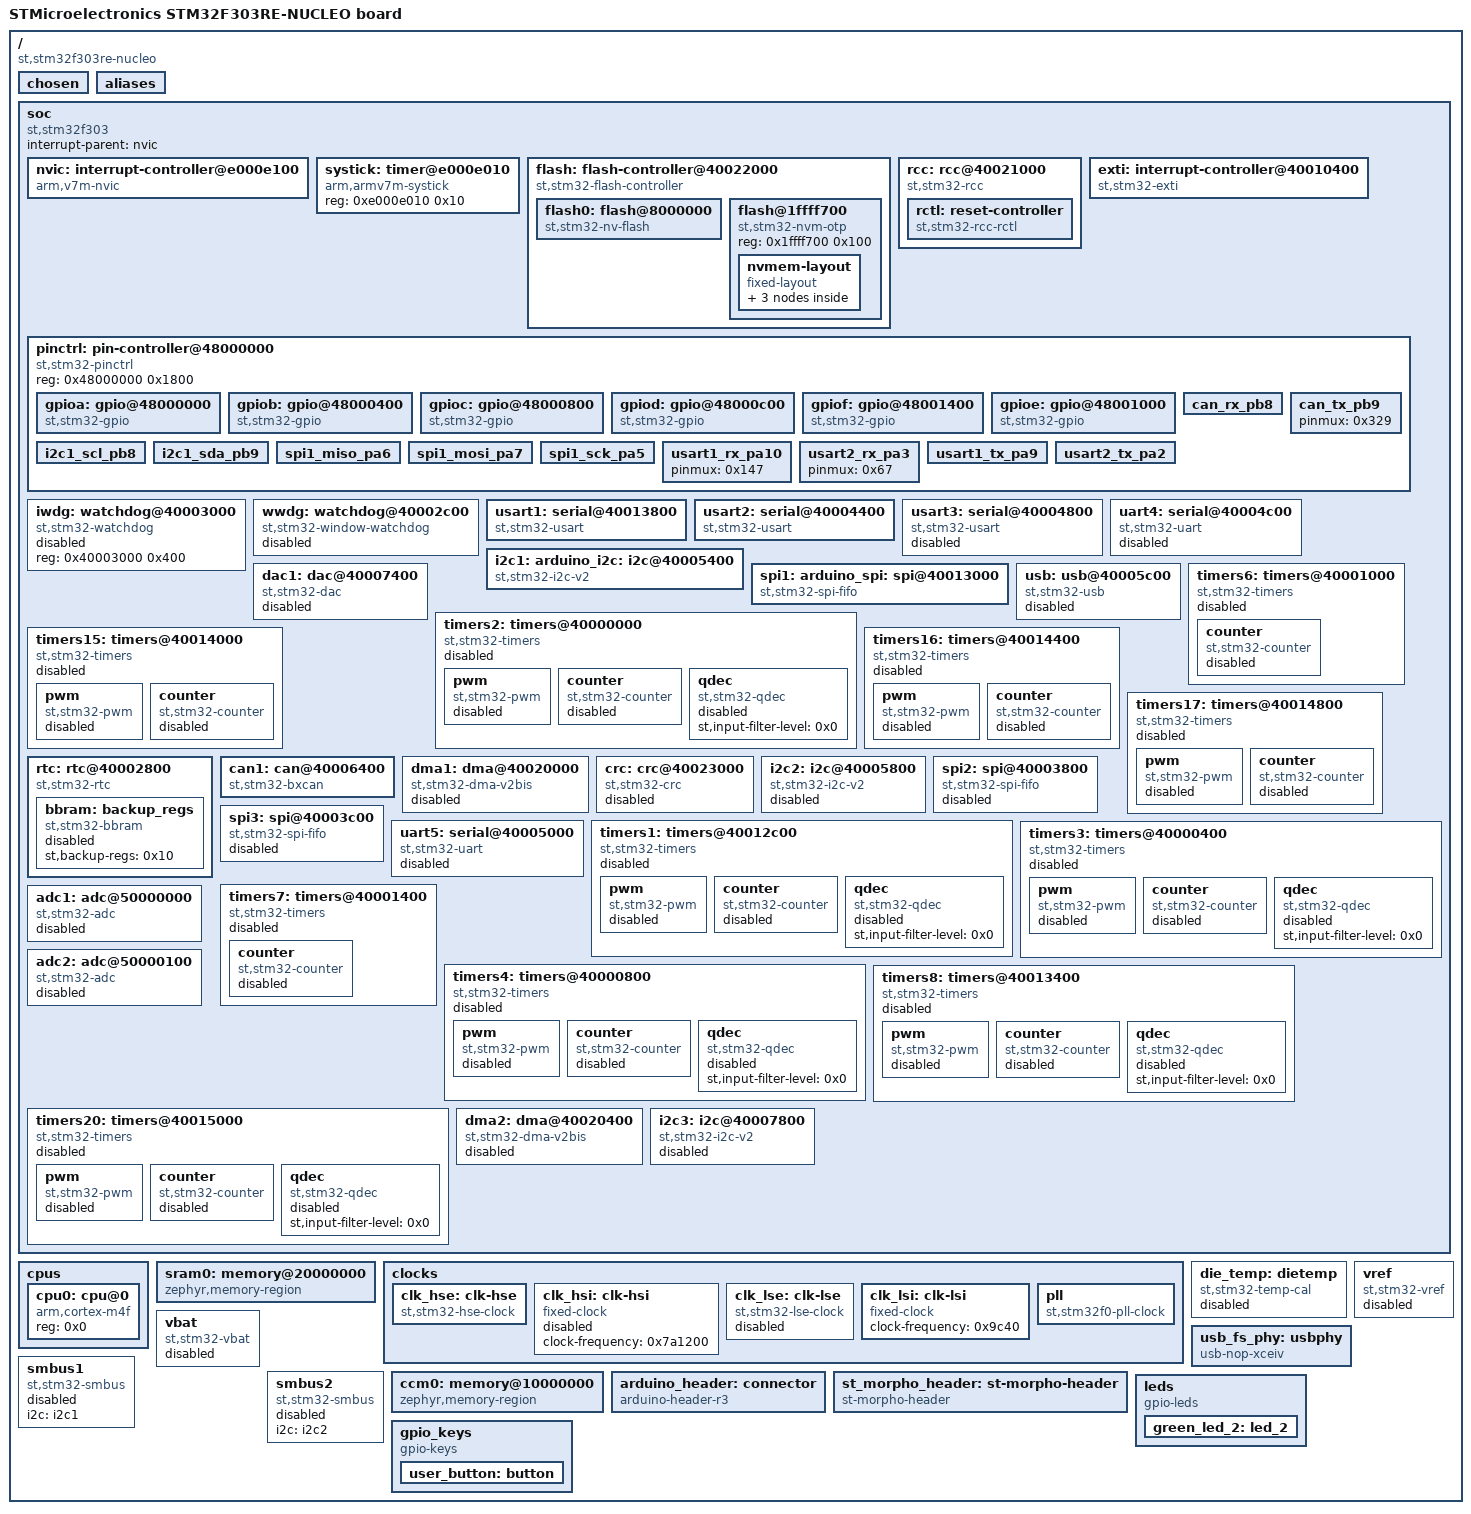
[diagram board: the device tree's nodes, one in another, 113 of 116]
/dts-v1/;

/* node '/' defined in zephyr/dts/common/skeleton.dtsi:9 */
/ {
	#address-cells = < 0x1 >;                              /* in zephyr/dts/common/skeleton.dtsi:10 */
	#size-cells = < 0x1 >;                                 /* in zephyr/dts/common/skeleton.dtsi:11 */
	model = "STMicroelectronics STM32F303RE-NUCLEO board"; /* in zephyr/boards/st/nucleo_f303re/nucleo_f303re.dts:15 */
	compatible = "st,stm32f303re-nucleo";                  /* in zephyr/boards/st/nucleo_f303re/nucleo_f303re.dts:16 */

	/* node '/chosen' defined in zephyr/dts/common/skeleton.dtsi:13 */
	chosen {
		zephyr,crc = &crc;                /* in zephyr/dts/arm/st/f3/stm32f3.dtsi:24 */
		zephyr,flash-controller = &flash; /* in zephyr/dts/arm/st/f3/stm32f3.dtsi:25 */
		zephyr,console = &usart2;         /* in zephyr/boards/st/nucleo_f303re/nucleo_f303re.dts:19 */
		zephyr,shell-uart = &usart2;      /* in zephyr/boards/st/nucleo_f303re/nucleo_f303re.dts:20 */
		zephyr,sram = &sram0;             /* in zephyr/boards/st/nucleo_f303re/nucleo_f303re.dts:21 */
		zephyr,flash = &flash0;           /* in zephyr/boards/st/nucleo_f303re/nucleo_f303re.dts:22 */
		zephyr,canbus = &can1;            /* in zephyr/boards/st/nucleo_f303re/nucleo_f303re.dts:23 */
	};

	/* node '/aliases' defined in zephyr/dts/common/skeleton.dtsi:15 */
	aliases {
		led0 = &green_led_2; /* in zephyr/boards/st/nucleo_f303re/nucleo_f303re.dts:46 */
		sw0 = &user_button;  /* in zephyr/boards/st/nucleo_f303re/nucleo_f303re.dts:47 */
	};

	/* node '/soc' defined in zephyr/dts/arm/armv7-m.dtsi:6 */
	soc {
		#address-cells = < 0x1 >;     /* in zephyr/dts/arm/armv7-m.dtsi:7 */
		#size-cells = < 0x1 >;        /* in zephyr/dts/arm/armv7-m.dtsi:8 */
		interrupt-parent = < &nvic >; /* in zephyr/dts/arm/armv7-m.dtsi:10 */
		ranges;                       /* in zephyr/dts/arm/armv7-m.dtsi:11 */
		compatible = "st,stm32f303",
		             "st,stm32f3",
		             "simple-bus";    /* in zephyr/dts/arm/st/f3/stm32f303.dtsi:12 */

		/* node '/soc/interrupt-controller@e000e100' defined in zephyr/dts/arm/armv7-m.dtsi:13 */
		nvic: interrupt-controller@e000e100 {
			#address-cells = < 0x1 >;            /* in zephyr/dts/arm/armv7-m.dtsi:14 */
			compatible = "arm,v7m-nvic";         /* in zephyr/dts/arm/armv7-m.dtsi:15 */
			reg = < 0xe000e100 0xc00 >;          /* in zephyr/dts/arm/armv7-m.dtsi:16 */
			interrupt-controller;                /* in zephyr/dts/arm/armv7-m.dtsi:17 */
			#interrupt-cells = < 0x2 >;          /* in zephyr/dts/arm/armv7-m.dtsi:18 */
			arm,num-irq-priority-bits = < 0x4 >; /* in zephyr/dts/arm/st/f3/stm32f3.dtsi:501 */
			phandle = < 0x1 >;                   /* in zephyr/dts/arm/armv7-m.dtsi:10 */
		};

		/* node '/soc/timer@e000e010' defined in zephyr/dts/arm/armv7-m.dtsi:21 */
		systick: timer@e000e010 {
			compatible = "arm,armv7m-systick"; /* in zephyr/dts/arm/armv7-m.dtsi:22 */
			reg = < 0xe000e010 0x10 >;         /* in zephyr/dts/arm/armv7-m.dtsi:23 */
		};

		/* node '/soc/flash-controller@40022000' defined in zephyr/dts/arm/st/f3/stm32f3.dtsi:81 */
		flash: flash-controller@40022000 {
			compatible = "st,stm32-flash-controller",
			             "st,stm32f1-flash-controller"; /* in zephyr/dts/arm/st/f3/stm32f3.dtsi:82 */
			reg = < 0x40022000 0x400 >;                 /* in zephyr/dts/arm/st/f3/stm32f3.dtsi:83 */
			interrupts = < 0x4 0x0 >;                   /* in zephyr/dts/arm/st/f3/stm32f3.dtsi:84 */
			clocks = < &rcc 0x14 0x10 >;                /* in zephyr/dts/arm/st/f3/stm32f3.dtsi:85 */
			#address-cells = < 0x1 >;                   /* in zephyr/dts/arm/st/f3/stm32f3.dtsi:87 */
			#size-cells = < 0x1 >;                      /* in zephyr/dts/arm/st/f3/stm32f3.dtsi:88 */
			ranges;                                     /* in zephyr/dts/arm/st/f3/stm32f3.dtsi:89 */

			/* node '/soc/flash-controller@40022000/flash@8000000' defined in zephyr/dts/arm/st/f3/stm32f3.dtsi:91 */
			flash0: flash@8000000 {
				compatible = "st,stm32-nv-flash",
				             "soc-nv-flash";        /* in zephyr/dts/arm/st/f3/stm32f3.dtsi:92 */
				#address-cells = < 0x1 >;           /* in zephyr/dts/arm/st/f3/stm32f3.dtsi:93 */
				#size-cells = < 0x1 >;              /* in zephyr/dts/arm/st/f3/stm32f3.dtsi:94 */
				write-block-size = < 0x2 >;         /* in zephyr/dts/arm/st/f3/stm32f3.dtsi:95 */
				erase-block-size = < 0x800 >;       /* in zephyr/dts/arm/st/f3/stm32f3.dtsi:96 */
				max-erase-time = < 0x28 >;          /* in zephyr/dts/arm/st/f3/stm32f3.dtsi:98 */
				reg = < 0x8000000 0x80000 >;        /* in zephyr/dts/arm/st/f3/stm32f303Xe.dtsi:23 */
				ranges = < 0x0 0x8000000 0x80000 >; /* in zephyr/dts/arm/st/f3/stm32f303Xe.dtsi:24 */
			};

			/* node '/soc/flash-controller@40022000/flash@1ffff700' defined in zephyr/dts/arm/st/f3/stm32f3.dtsi:105 */
			flash@1ffff700 {
				compatible = "st,stm32-nvm-otp"; /* in zephyr/dts/arm/st/f3/stm32f3.dtsi:106 */
				reg = < 0x1ffff700 0x100 >;      /* in zephyr/dts/arm/st/f3/stm32f3.dtsi:107 */

				/* node '/soc/flash-controller@40022000/flash@1ffff700/nvmem-layout' defined in zephyr/dts/arm/st/f3/stm32f3.dtsi:109 */
				nvmem-layout {
					compatible = "fixed-layout"; /* in zephyr/dts/arm/st/f3/stm32f3.dtsi:110 */
					#address-cells = < 0x1 >;    /* in zephyr/dts/arm/st/f3/stm32f3.dtsi:111 */
					#size-cells = < 0x1 >;       /* in zephyr/dts/arm/st/f3/stm32f3.dtsi:112 */

					/* node '/soc/flash-controller@40022000/flash@1ffff700/nvmem-layout/ts-cal1@b8' defined in zephyr/dts/arm/st/f3/stm32f3.dtsi:114 */
					ts_cal1_otp: ts-cal1@b8 {
						reg = < 0xb8 0x2 >;          /* in zephyr/dts/arm/st/f3/stm32f3.dtsi:115 */
						#nvmem-cell-cells = < 0x0 >; /* in zephyr/dts/arm/st/f3/stm32f3.dtsi:116 */
						read-only;                   /* in zephyr/dts/arm/st/f3/stm32f3.dtsi:117 */
						phandle = < 0x13 >;          /* in zephyr/dts/arm/st/f3/stm32f3.dtsi:462 */
					};

					/* node '/soc/flash-controller@40022000/flash@1ffff700/nvmem-layout/vrefint@ba' defined in zephyr/dts/arm/st/f3/stm32f3.dtsi:120 */
					vrefint_otp: vrefint@ba {
						reg = < 0xba 0x2 >;          /* in zephyr/dts/arm/st/f3/stm32f3.dtsi:121 */
						#nvmem-cell-cells = < 0x0 >; /* in zephyr/dts/arm/st/f3/stm32f3.dtsi:122 */
						read-only;                   /* in zephyr/dts/arm/st/f3/stm32f3.dtsi:123 */
						phandle = < 0x16 >;          /* in zephyr/dts/arm/st/f3/stm32f3.dtsi:473 */
					};

					/* node '/soc/flash-controller@40022000/flash@1ffff700/nvmem-layout/ts-cal2@c2' defined in zephyr/dts/arm/st/f3/stm32f3.dtsi:126 */
					ts_cal2_otp: ts-cal2@c2 {
						reg = < 0xc2 0x2 >;          /* in zephyr/dts/arm/st/f3/stm32f3.dtsi:127 */
						#nvmem-cell-cells = < 0x0 >; /* in zephyr/dts/arm/st/f3/stm32f3.dtsi:128 */
						read-only;                   /* in zephyr/dts/arm/st/f3/stm32f3.dtsi:129 */
						phandle = < 0x14 >;          /* in zephyr/dts/arm/st/f3/stm32f3.dtsi:462 */
					};
				};
			};
		};

		/* node '/soc/rcc@40021000' defined in zephyr/dts/arm/st/f3/stm32f3.dtsi:135 */
		rcc: rcc@40021000 {
			compatible = "st,stm32-rcc";     /* in zephyr/dts/arm/st/f3/stm32f3.dtsi:136 */
			#clock-cells = < 0x2 >;          /* in zephyr/dts/arm/st/f3/stm32f3.dtsi:137 */
			reg = < 0x40021000 0x400 >;      /* in zephyr/dts/arm/st/f3/stm32f3.dtsi:138 */
			clocks = < &pll >;               /* in zephyr/boards/st/nucleo_f303re/nucleo_f303re.dts:69 */
			clock-frequency = < 0x44aa200 >; /* in zephyr/boards/st/nucleo_f303re/nucleo_f303re.dts:70 */
			ahb-prescaler = < 0x1 >;         /* in zephyr/boards/st/nucleo_f303re/nucleo_f303re.dts:71 */
			apb1-prescaler = < 0x2 >;        /* in zephyr/boards/st/nucleo_f303re/nucleo_f303re.dts:72 */
			apb2-prescaler = < 0x1 >;        /* in zephyr/boards/st/nucleo_f303re/nucleo_f303re.dts:73 */
			phandle = < 0x2 >;               /* in zephyr/dts/arm/st/f3/stm32f3.dtsi:85 */

			/* node '/soc/rcc@40021000/reset-controller' defined in zephyr/dts/arm/st/f3/stm32f3.dtsi:140 */
			rctl: reset-controller {
				compatible = "st,stm32-rcc-rctl"; /* in zephyr/dts/arm/st/f3/stm32f3.dtsi:141 */
				#reset-cells = < 0x1 >;           /* in zephyr/dts/arm/st/f3/stm32f3.dtsi:142 */
				phandle = < 0x4 >;                /* in zephyr/dts/arm/st/f3/stm32f3.dtsi:227 */
			};
		};

		/* node '/soc/interrupt-controller@40010400' defined in zephyr/dts/arm/st/f3/stm32f3.dtsi:146 */
		exti: interrupt-controller@40010400 {
			compatible = "st,stm32-exti";  /* in zephyr/dts/arm/st/f3/stm32f3.dtsi:147 */
			interrupt-controller;          /* in zephyr/dts/arm/st/f3/stm32f3.dtsi:148 */
			#interrupt-cells = < 0x1 >;    /* in zephyr/dts/arm/st/f3/stm32f3.dtsi:149 */
			#address-cells = < 0x0 >;      /* in zephyr/dts/arm/st/f3/stm32f3.dtsi:150 */
			reg = < 0x40010400 0x400 >;    /* in zephyr/dts/arm/st/f3/stm32f3.dtsi:151 */
			clocks = < &rcc 0x18 0x1 >;    /* in zephyr/dts/arm/st/f3/stm32f3.dtsi:152 */
			num-lines = < 0x20 >;          /* in zephyr/dts/arm/st/f3/stm32f3.dtsi:153 */
			interrupts = < 0x6 0x0 >,
			             < 0x7 0x0 >,
			             < 0x8 0x0 >,
			             < 0x9 0x0 >,
			             < 0xa 0x0 >,
			             < 0x17 0x0 >,
			             < 0x28 0x0 >;     /* in zephyr/dts/arm/st/f3/stm32f3.dtsi:154 */
			interrupt-names = "line0",
			                  "line1",
			                  "line2",
			                  "line3",
			                  "line4",
			                  "line5-9",
			                  "line10-15"; /* in zephyr/dts/arm/st/f3/stm32f3.dtsi:156 */
			line-ranges = < 0x0 0x1 >,
			              < 0x1 0x1 >,
			              < 0x2 0x1 >,
			              < 0x3 0x1 >,
			              < 0x4 0x1 >,
			              < 0x5 0x5 >,
			              < 0xa 0x6 >;     /* in zephyr/dts/arm/st/f3/stm32f3.dtsi:158 */
		};

		/* node '/soc/pin-controller@48000000' defined in zephyr/dts/arm/st/f3/stm32f3.dtsi:162 */
		pinctrl: pin-controller@48000000 {
			compatible = "st,stm32-pinctrl"; /* in zephyr/dts/arm/st/f3/stm32f3.dtsi:163 */
			#address-cells = < 0x1 >;        /* in zephyr/dts/arm/st/f3/stm32f3.dtsi:164 */
			#size-cells = < 0x1 >;           /* in zephyr/dts/arm/st/f3/stm32f3.dtsi:165 */
			reg = < 0x48000000 0x1800 >;     /* in zephyr/dts/arm/st/f3/stm32f3.dtsi:166 */

			/* node '/soc/pin-controller@48000000/gpio@48000000' defined in zephyr/dts/arm/st/f3/stm32f3.dtsi:168 */
			gpioa: gpio@48000000 {
				compatible = "st,stm32-gpio";   /* in zephyr/dts/arm/st/f3/stm32f3.dtsi:169 */
				gpio-controller;                /* in zephyr/dts/arm/st/f3/stm32f3.dtsi:170 */
				#gpio-cells = < 0x2 >;          /* in zephyr/dts/arm/st/f3/stm32f3.dtsi:171 */
				reg = < 0x48000000 0x400 >;     /* in zephyr/dts/arm/st/f3/stm32f3.dtsi:172 */
				clocks = < &rcc 0x14 0x20000 >; /* in zephyr/dts/arm/st/f3/stm32f3.dtsi:173 */
				phandle = < 0x19 >;             /* in zephyr/boards/st/nucleo_f303re/arduino_r3_connector.dtsi:15 */
			};

			/* node '/soc/pin-controller@48000000/gpio@48000400' defined in zephyr/dts/arm/st/f3/stm32f3.dtsi:176 */
			gpiob: gpio@48000400 {
				compatible = "st,stm32-gpio";   /* in zephyr/dts/arm/st/f3/stm32f3.dtsi:177 */
				gpio-controller;                /* in zephyr/dts/arm/st/f3/stm32f3.dtsi:178 */
				#gpio-cells = < 0x2 >;          /* in zephyr/dts/arm/st/f3/stm32f3.dtsi:179 */
				reg = < 0x48000400 0x400 >;     /* in zephyr/dts/arm/st/f3/stm32f3.dtsi:180 */
				clocks = < &rcc 0x14 0x40000 >; /* in zephyr/dts/arm/st/f3/stm32f3.dtsi:181 */
				phandle = < 0xb >;              /* in zephyr/boards/st/nucleo_f303re/nucleo_f303re.dts:107 */
			};

			/* node '/soc/pin-controller@48000000/gpio@48000800' defined in zephyr/dts/arm/st/f3/stm32f3.dtsi:184 */
			gpioc: gpio@48000800 {
				compatible = "st,stm32-gpio";   /* in zephyr/dts/arm/st/f3/stm32f3.dtsi:185 */
				gpio-controller;                /* in zephyr/dts/arm/st/f3/stm32f3.dtsi:186 */
				#gpio-cells = < 0x2 >;          /* in zephyr/dts/arm/st/f3/stm32f3.dtsi:187 */
				reg = < 0x48000800 0x400 >;     /* in zephyr/dts/arm/st/f3/stm32f3.dtsi:188 */
				clocks = < &rcc 0x14 0x80000 >; /* in zephyr/dts/arm/st/f3/stm32f3.dtsi:189 */
				phandle = < 0x1a >;             /* in zephyr/boards/st/nucleo_f303re/arduino_r3_connector.dtsi:15 */
			};

			/* node '/soc/pin-controller@48000000/gpio@48000c00' defined in zephyr/dts/arm/st/f3/stm32f3.dtsi:192 */
			gpiod: gpio@48000c00 {
				compatible = "st,stm32-gpio";    /* in zephyr/dts/arm/st/f3/stm32f3.dtsi:193 */
				gpio-controller;                 /* in zephyr/dts/arm/st/f3/stm32f3.dtsi:194 */
				#gpio-cells = < 0x2 >;           /* in zephyr/dts/arm/st/f3/stm32f3.dtsi:195 */
				reg = < 0x48000c00 0x400 >;      /* in zephyr/dts/arm/st/f3/stm32f3.dtsi:196 */
				clocks = < &rcc 0x14 0x100000 >; /* in zephyr/dts/arm/st/f3/stm32f3.dtsi:197 */
				phandle = < 0x1b >;              /* in zephyr/boards/st/nucleo_f303re/st_morpho_connector.dtsi:15 */
			};

			/* node '/soc/pin-controller@48000000/gpio@48001400' defined in zephyr/dts/arm/st/f3/stm32f3.dtsi:200 */
			gpiof: gpio@48001400 {
				compatible = "st,stm32-gpio";    /* in zephyr/dts/arm/st/f3/stm32f3.dtsi:201 */
				gpio-controller;                 /* in zephyr/dts/arm/st/f3/stm32f3.dtsi:202 */
				#gpio-cells = < 0x2 >;           /* in zephyr/dts/arm/st/f3/stm32f3.dtsi:203 */
				reg = < 0x48001400 0x400 >;      /* in zephyr/dts/arm/st/f3/stm32f3.dtsi:204 */
				clocks = < &rcc 0x14 0x400000 >; /* in zephyr/dts/arm/st/f3/stm32f3.dtsi:205 */
				phandle = < 0x1c >;              /* in zephyr/boards/st/nucleo_f303re/st_morpho_connector.dtsi:15 */
			};

			/* node '/soc/pin-controller@48000000/gpio@48001000' defined in zephyr/dts/arm/st/f3/stm32f303.dtsi:67 */
			gpioe: gpio@48001000 {
				compatible = "st,stm32-gpio";    /* in zephyr/dts/arm/st/f3/stm32f303.dtsi:68 */
				gpio-controller;                 /* in zephyr/dts/arm/st/f3/stm32f303.dtsi:69 */
				#gpio-cells = < 0x2 >;           /* in zephyr/dts/arm/st/f3/stm32f303.dtsi:70 */
				reg = < 0x48001000 0x400 >;      /* in zephyr/dts/arm/st/f3/stm32f303.dtsi:71 */
				clocks = < &rcc 0x14 0x200000 >; /* in zephyr/dts/arm/st/f3/stm32f303.dtsi:72 */
			};

			/* node '/soc/pin-controller@48000000/can_rx_pb8' defined in modules/hal/stm32/dts/st/f3/stm32f303r(d-e)tx-pinctrl.dtsi:334 */
			can_rx_pb8: can_rx_pb8 {
				pinmux = < 0x309 >; /* in modules/hal/stm32/dts/st/f3/stm32f303r(d-e)tx-pinctrl.dtsi:335 */
				bias-pull-up;       /* in modules/hal/stm32/dts/st/f3/stm32f303r(d-e)tx-pinctrl.dtsi:336 */
				phandle = < 0x10 >; /* in zephyr/boards/st/nucleo_f303re/nucleo_f303re.dts:97 */
			};

			/* node '/soc/pin-controller@48000000/can_tx_pb9' defined in modules/hal/stm32/dts/st/f3/stm32f303r(d-e)tx-pinctrl.dtsi:345 */
			can_tx_pb9: can_tx_pb9 {
				pinmux = < 0x329 >; /* in modules/hal/stm32/dts/st/f3/stm32f303r(d-e)tx-pinctrl.dtsi:346 */
				phandle = < 0x11 >; /* in zephyr/boards/st/nucleo_f303re/nucleo_f303re.dts:97 */
			};

			/* node '/soc/pin-controller@48000000/i2c1_scl_pb8' defined in modules/hal/stm32/dts/st/f3/stm32f303r(d-e)tx-pinctrl.dtsi:549 */
			i2c1_scl_pb8: i2c1_scl_pb8 {
				pinmux = < 0x304 >; /* in modules/hal/stm32/dts/st/f3/stm32f303r(d-e)tx-pinctrl.dtsi:550 */
				bias-pull-up;       /* in modules/hal/stm32/dts/st/f3/stm32f303r(d-e)tx-pinctrl.dtsi:551 */
				drive-open-drain;   /* in modules/hal/stm32/dts/st/f3/stm32f303r(d-e)tx-pinctrl.dtsi:552 */
				phandle = < 0x9 >;  /* in zephyr/boards/st/nucleo_f303re/nucleo_f303re.dts:103 */
			};

			/* node '/soc/pin-controller@48000000/i2c1_sda_pb9' defined in modules/hal/stm32/dts/st/f3/stm32f303r(d-e)tx-pinctrl.dtsi:587 */
			i2c1_sda_pb9: i2c1_sda_pb9 {
				pinmux = < 0x324 >; /* in modules/hal/stm32/dts/st/f3/stm32f303r(d-e)tx-pinctrl.dtsi:588 */
				bias-pull-up;       /* in modules/hal/stm32/dts/st/f3/stm32f303r(d-e)tx-pinctrl.dtsi:589 */
				drive-open-drain;   /* in modules/hal/stm32/dts/st/f3/stm32f303r(d-e)tx-pinctrl.dtsi:590 */
				phandle = < 0xa >;  /* in zephyr/boards/st/nucleo_f303re/nucleo_f303re.dts:103 */
			};

			/* node '/soc/pin-controller@48000000/spi1_miso_pa6' defined in modules/hal/stm32/dts/st/f3/stm32f303r(d-e)tx-pinctrl.dtsi:852 */
			spi1_miso_pa6: spi1_miso_pa6 {
				pinmux = < 0xc5 >;             /* in modules/hal/stm32/dts/st/f3/stm32f303r(d-e)tx-pinctrl.dtsi:853 */
				bias-pull-down;                /* in modules/hal/stm32/dts/st/f3/stm32f303r(d-e)tx-pinctrl.dtsi:854 */
				slew-rate = "very-high-speed"; /* in modules/hal/stm32/dts/st/f3/stm32f303r(d-e)tx-pinctrl.dtsi:855 */
				phandle = < 0xd >;             /* in nucleo_f303re.overlay:2 */
			};

			/* node '/soc/pin-controller@48000000/spi1_mosi_pa7' defined in modules/hal/stm32/dts/st/f3/stm32f303r(d-e)tx-pinctrl.dtsi:890 */
			spi1_mosi_pa7: spi1_mosi_pa7 {
				pinmux = < 0xe5 >;             /* in modules/hal/stm32/dts/st/f3/stm32f303r(d-e)tx-pinctrl.dtsi:891 */
				bias-pull-down;                /* in modules/hal/stm32/dts/st/f3/stm32f303r(d-e)tx-pinctrl.dtsi:892 */
				slew-rate = "very-high-speed"; /* in modules/hal/stm32/dts/st/f3/stm32f303r(d-e)tx-pinctrl.dtsi:893 */
				phandle = < 0xc >;             /* in nucleo_f303re.overlay:2 */
			};

			/* node '/soc/pin-controller@48000000/spi1_sck_pa5' defined in modules/hal/stm32/dts/st/f3/stm32f303r(d-e)tx-pinctrl.dtsi:966 */
			spi1_sck_pa5: spi1_sck_pa5 {
				pinmux = < 0xa5 >;             /* in modules/hal/stm32/dts/st/f3/stm32f303r(d-e)tx-pinctrl.dtsi:967 */
				bias-pull-down;                /* in modules/hal/stm32/dts/st/f3/stm32f303r(d-e)tx-pinctrl.dtsi:968 */
				slew-rate = "very-high-speed"; /* in modules/hal/stm32/dts/st/f3/stm32f303r(d-e)tx-pinctrl.dtsi:969 */
				phandle = < 0xe >;             /* in nucleo_f303re.overlay:2 */
			};

			/* node '/soc/pin-controller@48000000/usart1_rx_pa10' defined in modules/hal/stm32/dts/st/f3/stm32f303r(d-e)tx-pinctrl.dtsi:1578 */
			usart1_rx_pa10: usart1_rx_pa10 {
				pinmux = < 0x147 >; /* in modules/hal/stm32/dts/st/f3/stm32f303r(d-e)tx-pinctrl.dtsi:1579 */
				phandle = < 0x6 >;  /* in zephyr/boards/st/nucleo_f303re/nucleo_f303re.dts:84 */
			};

			/* node '/soc/pin-controller@48000000/usart2_rx_pa3' defined in modules/hal/stm32/dts/st/f3/stm32f303r(d-e)tx-pinctrl.dtsi:1590 */
			usart2_rx_pa3: usart2_rx_pa3 {
				pinmux = < 0x67 >; /* in modules/hal/stm32/dts/st/f3/stm32f303r(d-e)tx-pinctrl.dtsi:1591 */
				phandle = < 0x8 >; /* in zephyr/boards/st/nucleo_f303re/nucleo_f303re.dts:77 */
			};

			/* node '/soc/pin-controller@48000000/usart1_tx_pa9' defined in modules/hal/stm32/dts/st/f3/stm32f303r(d-e)tx-pinctrl.dtsi:1624 */
			usart1_tx_pa9: usart1_tx_pa9 {
				pinmux = < 0x127 >; /* in modules/hal/stm32/dts/st/f3/stm32f303r(d-e)tx-pinctrl.dtsi:1625 */
				bias-pull-up;       /* in modules/hal/stm32/dts/st/f3/stm32f303r(d-e)tx-pinctrl.dtsi:1626 */
				phandle = < 0x5 >;  /* in zephyr/boards/st/nucleo_f303re/nucleo_f303re.dts:84 */
			};

			/* node '/soc/pin-controller@48000000/usart2_tx_pa2' defined in modules/hal/stm32/dts/st/f3/stm32f303r(d-e)tx-pinctrl.dtsi:1639 */
			usart2_tx_pa2: usart2_tx_pa2 {
				pinmux = < 0x47 >; /* in modules/hal/stm32/dts/st/f3/stm32f303r(d-e)tx-pinctrl.dtsi:1640 */
				bias-pull-up;      /* in modules/hal/stm32/dts/st/f3/stm32f303r(d-e)tx-pinctrl.dtsi:1641 */
				phandle = < 0x7 >; /* in zephyr/boards/st/nucleo_f303re/nucleo_f303re.dts:77 */
			};
		};

		/* node '/soc/watchdog@40003000' defined in zephyr/dts/arm/st/f3/stm32f3.dtsi:209 */
		iwdg: watchdog@40003000 {
			compatible = "st,stm32-watchdog"; /* in zephyr/dts/arm/st/f3/stm32f3.dtsi:210 */
			reg = < 0x40003000 0x400 >;       /* in zephyr/dts/arm/st/f3/stm32f3.dtsi:211 */
			status = "disabled";              /* in zephyr/dts/arm/st/f3/stm32f3.dtsi:212 */
		};

		/* node '/soc/watchdog@40002c00' defined in zephyr/dts/arm/st/f3/stm32f3.dtsi:215 */
		wwdg: watchdog@40002c00 {
			compatible = "st,stm32-window-watchdog"; /* in zephyr/dts/arm/st/f3/stm32f3.dtsi:216 */
			reg = < 0x40002c00 0x400 >;              /* in zephyr/dts/arm/st/f3/stm32f3.dtsi:217 */
			clocks = < &rcc 0x1c 0x800 >;            /* in zephyr/dts/arm/st/f3/stm32f3.dtsi:218 */
			interrupts = < 0x0 0x0 >;                /* in zephyr/dts/arm/st/f3/stm32f3.dtsi:219 */
			status = "disabled";                     /* in zephyr/dts/arm/st/f3/stm32f3.dtsi:220 */
		};

		/* node '/soc/serial@40013800' defined in zephyr/dts/arm/st/f3/stm32f3.dtsi:223 */
		usart1: serial@40013800 {
			compatible = "st,stm32-usart",
			             "st,stm32-uart";                   /* in zephyr/dts/arm/st/f3/stm32f3.dtsi:224 */
			reg = < 0x40013800 0x400 >;                     /* in zephyr/dts/arm/st/f3/stm32f3.dtsi:225 */
			clocks = < &rcc 0x18 0x4000 >;                  /* in zephyr/dts/arm/st/f3/stm32f3.dtsi:226 */
			resets = < &rctl 0x18e >;                       /* in zephyr/dts/arm/st/f3/stm32f3.dtsi:227 */
			interrupts = < 0x25 0x0 >;                      /* in zephyr/dts/arm/st/f3/stm32f3.dtsi:228 */
			pinctrl-0 = < &usart1_tx_pa9 &usart1_rx_pa10 >; /* in zephyr/boards/st/nucleo_f303re/nucleo_f303re.dts:84 */
			pinctrl-names = "default";                      /* in zephyr/boards/st/nucleo_f303re/nucleo_f303re.dts:85 */
			current-speed = < 0x1c200 >;                    /* in zephyr/boards/st/nucleo_f303re/nucleo_f303re.dts:86 */
			status = "okay";                                /* in zephyr/boards/st/nucleo_f303re/nucleo_f303re.dts:87 */
		};

		/* node '/soc/serial@40004400' defined in zephyr/dts/arm/st/f3/stm32f3.dtsi:232 */
		usart2: serial@40004400 {
			compatible = "st,stm32-usart",
			             "st,stm32-uart";                  /* in zephyr/dts/arm/st/f3/stm32f3.dtsi:233 */
			reg = < 0x40004400 0x400 >;                    /* in zephyr/dts/arm/st/f3/stm32f3.dtsi:234 */
			clocks = < &rcc 0x1c 0x20000 >;                /* in zephyr/dts/arm/st/f3/stm32f3.dtsi:235 */
			resets = < &rctl 0x211 >;                      /* in zephyr/dts/arm/st/f3/stm32f3.dtsi:236 */
			interrupts = < 0x26 0x0 >;                     /* in zephyr/dts/arm/st/f3/stm32f3.dtsi:237 */
			pinctrl-0 = < &usart2_tx_pa2 &usart2_rx_pa3 >; /* in zephyr/boards/st/nucleo_f303re/nucleo_f303re.dts:77 */
			pinctrl-names = "default";                     /* in zephyr/boards/st/nucleo_f303re/nucleo_f303re.dts:78 */
			current-speed = < 0x1c200 >;                   /* in zephyr/boards/st/nucleo_f303re/nucleo_f303re.dts:79 */
			status = "okay";                               /* in zephyr/boards/st/nucleo_f303re/nucleo_f303re.dts:80 */
		};

		/* node '/soc/serial@40004800' defined in zephyr/dts/arm/st/f3/stm32f3.dtsi:241 */
		usart3: serial@40004800 {
			compatible = "st,stm32-usart",
			             "st,stm32-uart";   /* in zephyr/dts/arm/st/f3/stm32f3.dtsi:242 */
			reg = < 0x40004800 0x400 >;     /* in zephyr/dts/arm/st/f3/stm32f3.dtsi:243 */
			clocks = < &rcc 0x1c 0x40000 >; /* in zephyr/dts/arm/st/f3/stm32f3.dtsi:244 */
			resets = < &rctl 0x212 >;       /* in zephyr/dts/arm/st/f3/stm32f3.dtsi:245 */
			interrupts = < 0x27 0x0 >;      /* in zephyr/dts/arm/st/f3/stm32f3.dtsi:246 */
			status = "disabled";            /* in zephyr/dts/arm/st/f3/stm32f3.dtsi:247 */
		};

		/* node '/soc/serial@40004c00' defined in zephyr/dts/arm/st/f3/stm32f3.dtsi:250 */
		uart4: serial@40004c00 {
			compatible = "st,stm32-uart";   /* in zephyr/dts/arm/st/f3/stm32f3.dtsi:251 */
			reg = < 0x40004c00 0x400 >;     /* in zephyr/dts/arm/st/f3/stm32f3.dtsi:252 */
			clocks = < &rcc 0x1c 0x80000 >; /* in zephyr/dts/arm/st/f3/stm32f3.dtsi:253 */
			resets = < &rctl 0x213 >;       /* in zephyr/dts/arm/st/f3/stm32f3.dtsi:254 */
			interrupts = < 0x34 0x0 >;      /* in zephyr/dts/arm/st/f3/stm32f3.dtsi:255 */
			status = "disabled";            /* in zephyr/dts/arm/st/f3/stm32f3.dtsi:256 */
		};

		/* node '/soc/i2c@40005400' defined in zephyr/dts/arm/st/f3/stm32f3.dtsi:259 */
		i2c1: arduino_i2c: i2c@40005400 {
			compatible = "st,stm32-i2c-v2";              /* in zephyr/dts/arm/st/f3/stm32f3.dtsi:260 */
			#address-cells = < 0x1 >;                    /* in zephyr/dts/arm/st/f3/stm32f3.dtsi:262 */
			#size-cells = < 0x0 >;                       /* in zephyr/dts/arm/st/f3/stm32f3.dtsi:263 */
			reg = < 0x40005400 0x400 >;                  /* in zephyr/dts/arm/st/f3/stm32f3.dtsi:264 */
			clocks = < &rcc 0x1c 0x200000 >,
			         < &rcc 0x1 0x1040030 >;             /* in zephyr/dts/arm/st/f3/stm32f3.dtsi:265 */
			interrupts = < 0x1f 0x0 >,
			             < 0x20 0x0 >;                   /* in zephyr/dts/arm/st/f3/stm32f3.dtsi:270 */
			interrupt-names = "event",
			                  "error";                   /* in zephyr/dts/arm/st/f3/stm32f3.dtsi:271 */
			pinctrl-0 = < &i2c1_scl_pb8 &i2c1_sda_pb9 >; /* in zephyr/boards/st/nucleo_f303re/nucleo_f303re.dts:103 */
			status = "okay";                             /* in zephyr/boards/st/nucleo_f303re/nucleo_f303re.dts:104 */
			pinctrl-names = "default";                   /* in zephyr/boards/st/nucleo_f303re/nucleo_f303re.dts:105 */
			clock-frequency = < 0x186a0 >;               /* in zephyr/boards/st/nucleo_f303re/nucleo_f303re.dts:106 */
			scl-gpios = < &gpiob 0x8 0x0 >;              /* in zephyr/boards/st/nucleo_f303re/nucleo_f303re.dts:107 */
			sda-gpios = < &gpiob 0x9 0x0 >;              /* in zephyr/boards/st/nucleo_f303re/nucleo_f303re.dts:108 */
			phandle = < 0x17 >;                          /* in zephyr/dts/arm/st/f3/stm32f3.dtsi:495 */
		};

		/* node '/soc/spi@40013000' defined in zephyr/dts/arm/st/f3/stm32f3.dtsi:275 */
		spi1: arduino_spi: spi@40013000 {
			compatible = "st,stm32-spi-fifo",
			             "st,stm32-spi";                                 /* in zephyr/dts/arm/st/f3/stm32f3.dtsi:276 */
			#address-cells = < 0x1 >;                                    /* in zephyr/dts/arm/st/f3/stm32f3.dtsi:277 */
			#size-cells = < 0x0 >;                                       /* in zephyr/dts/arm/st/f3/stm32f3.dtsi:278 */
			reg = < 0x40013000 0x400 >;                                  /* in zephyr/dts/arm/st/f3/stm32f3.dtsi:279 */
			clocks = < &rcc 0x18 0x1000 >;                               /* in zephyr/dts/arm/st/f3/stm32f3.dtsi:280 */
			interrupts = < 0x23 0x0 >;                                   /* in zephyr/dts/arm/st/f3/stm32f3.dtsi:281 */
			st,spi-data-width = "full-4-to-16-bit";                      /* in zephyr/dts/arm/st/f3/stm32f3.dtsi:282 */
			pinctrl-0 = < &spi1_mosi_pa7 &spi1_miso_pa6 &spi1_sck_pa5 >; /* in nucleo_f303re.overlay:2 */
			pinctrl-names = "default";                                   /* in nucleo_f303re.overlay:3 */
			cs-gpios = < &gpiob 0x6 0x0 >;                               /* in nucleo_f303re.overlay:4 */
			status = "okay";                                             /* in nucleo_f303re.overlay:5 */
		};

		/* node '/soc/dac@40007400' defined in zephyr/dts/arm/st/f3/stm32f3.dtsi:286 */
		dac1: dac@40007400 {
			compatible = "st,stm32-dac";       /* in zephyr/dts/arm/st/f3/stm32f3.dtsi:287 */
			reg = < 0x40007400 0x400 >;        /* in zephyr/dts/arm/st/f3/stm32f3.dtsi:288 */
			clocks = < &rcc 0x1c 0x20000000 >; /* in zephyr/dts/arm/st/f3/stm32f3.dtsi:289 */
			status = "disabled";               /* in zephyr/dts/arm/st/f3/stm32f3.dtsi:290 */
			#io-channel-cells = < 0x1 >;       /* in zephyr/dts/arm/st/f3/stm32f3.dtsi:291 */
		};

		/* node '/soc/usb@40005c00' defined in zephyr/dts/arm/st/f3/stm32f3.dtsi:294 */
		usb: usb@40005c00 {
			compatible = "st,stm32-usb";     /* in zephyr/dts/arm/st/f3/stm32f3.dtsi:295 */
			reg = < 0x40005c00 0x400 >;      /* in zephyr/dts/arm/st/f3/stm32f3.dtsi:296 */
			interrupt-names = "usb";         /* in zephyr/dts/arm/st/f3/stm32f3.dtsi:298 */
			num-bidir-endpoints = < 0x8 >;   /* in zephyr/dts/arm/st/f3/stm32f3.dtsi:299 */
			ram-size = < 0x200 >;            /* in zephyr/dts/arm/st/f3/stm32f3.dtsi:300 */
			maximum-speed = "full-speed";    /* in zephyr/dts/arm/st/f3/stm32f3.dtsi:301 */
			phys = < &usb_fs_phy >;          /* in zephyr/dts/arm/st/f3/stm32f3.dtsi:302 */
			clocks = < &rcc 0x1c 0x800000 >; /* in zephyr/dts/arm/st/f3/stm32f3.dtsi:303 */
			status = "disabled";             /* in zephyr/dts/arm/st/f3/stm32f3.dtsi:304 */
			interrupts = < 0x4b 0x0 >;       /* in zephyr/dts/arm/st/f3/stm32f303.dtsi:16 */
		};

		/* node '/soc/timers@40000000' defined in zephyr/dts/arm/st/f3/stm32f3.dtsi:307 */
		timers2: timers@40000000 {
			compatible = "st,stm32-timers"; /* in zephyr/dts/arm/st/f3/stm32f3.dtsi:308 */
			reg = < 0x40000000 0x400 >;     /* in zephyr/dts/arm/st/f3/stm32f3.dtsi:309 */
			resets = < &rctl 0x200 >;       /* in zephyr/dts/arm/st/f3/stm32f3.dtsi:312 */
			interrupts = < 0x1c 0x0 >;      /* in zephyr/dts/arm/st/f3/stm32f3.dtsi:313 */
			interrupt-names = "global";     /* in zephyr/dts/arm/st/f3/stm32f3.dtsi:314 */
			st,prescaler = < 0x0 >;         /* in zephyr/dts/arm/st/f3/stm32f3.dtsi:315 */
			status = "disabled";            /* in zephyr/dts/arm/st/f3/stm32f3.dtsi:316 */
			clocks = < &rcc 0x1c 0x1 >,
			         < &rcc 0x6 0x180030 >; /* in zephyr/dts/arm/st/f3/stm32f303Xe.dtsi:29 */

			/* node '/soc/timers@40000000/pwm' defined in zephyr/dts/arm/st/f3/stm32f3.dtsi:318 */
			pwm {
				compatible = "st,stm32-pwm"; /* in zephyr/dts/arm/st/f3/stm32f3.dtsi:319 */
				status = "disabled";         /* in zephyr/dts/arm/st/f3/stm32f3.dtsi:320 */
				#pwm-cells = < 0x3 >;        /* in zephyr/dts/arm/st/f3/stm32f3.dtsi:321 */
			};

			/* node '/soc/timers@40000000/counter' defined in zephyr/dts/arm/st/f3/stm32f3.dtsi:324 */
			counter {
				compatible = "st,stm32-counter"; /* in zephyr/dts/arm/st/f3/stm32f3.dtsi:325 */
				status = "disabled";             /* in zephyr/dts/arm/st/f3/stm32f3.dtsi:326 */
			};

			/* node '/soc/timers@40000000/qdec' defined in zephyr/dts/arm/st/f3/stm32f3.dtsi:329 */
			qdec {
				compatible = "st,stm32-qdec";    /* in zephyr/dts/arm/st/f3/stm32f3.dtsi:330 */
				st,input-filter-level = < 0x0 >; /* in zephyr/dts/arm/st/f3/stm32f3.dtsi:331 */
				status = "disabled";             /* in zephyr/dts/arm/st/f3/stm32f3.dtsi:332 */
			};
		};

		/* node '/soc/timers@40001000' defined in zephyr/dts/arm/st/f3/stm32f3.dtsi:336 */
		timers6: timers@40001000 {
			compatible = "st,stm32-timers"; /* in zephyr/dts/arm/st/f3/stm32f3.dtsi:337 */
			reg = < 0x40001000 0x400 >;     /* in zephyr/dts/arm/st/f3/stm32f3.dtsi:338 */
			clocks = < &rcc 0x1c 0x10 >,
			         < &rcc 0x6 0xff >;     /* in zephyr/dts/arm/st/f3/stm32f3.dtsi:339 */
			resets = < &rctl 0x204 >;       /* in zephyr/dts/arm/st/f3/stm32f3.dtsi:341 */
			interrupts = < 0x36 0x0 >;      /* in zephyr/dts/arm/st/f3/stm32f3.dtsi:342 */
			interrupt-names = "global";     /* in zephyr/dts/arm/st/f3/stm32f3.dtsi:343 */
			st,prescaler = < 0x0 >;         /* in zephyr/dts/arm/st/f3/stm32f3.dtsi:344 */
			status = "disabled";            /* in zephyr/dts/arm/st/f3/stm32f3.dtsi:345 */

			/* node '/soc/timers@40001000/counter' defined in zephyr/dts/arm/st/f3/stm32f3.dtsi:347 */
			counter {
				compatible = "st,stm32-counter"; /* in zephyr/dts/arm/st/f3/stm32f3.dtsi:348 */
				status = "disabled";             /* in zephyr/dts/arm/st/f3/stm32f3.dtsi:349 */
			};
		};

		/* node '/soc/timers@40014000' defined in zephyr/dts/arm/st/f3/stm32f3.dtsi:353 */
		timers15: timers@40014000 {
			compatible = "st,stm32-timers"; /* in zephyr/dts/arm/st/f3/stm32f3.dtsi:354 */
			reg = < 0x40014000 0x400 >;     /* in zephyr/dts/arm/st/f3/stm32f3.dtsi:355 */
			resets = < &rctl 0x190 >;       /* in zephyr/dts/arm/st/f3/stm32f3.dtsi:358 */
			interrupts = < 0x18 0x0 >;      /* in zephyr/dts/arm/st/f3/stm32f3.dtsi:359 */
			interrupt-names = "global";     /* in zephyr/dts/arm/st/f3/stm32f3.dtsi:360 */
			st,prescaler = < 0x0 >;         /* in zephyr/dts/arm/st/f3/stm32f3.dtsi:361 */
			status = "disabled";            /* in zephyr/dts/arm/st/f3/stm32f3.dtsi:362 */
			clocks = < &rcc 0x18 0x10000 >,
			         < &rcc 0x7 0xa0030 >;  /* in zephyr/dts/arm/st/f3/stm32f303Xe.dtsi:97 */

			/* node '/soc/timers@40014000/pwm' defined in zephyr/dts/arm/st/f3/stm32f3.dtsi:364 */
			pwm {
				compatible = "st,stm32-pwm"; /* in zephyr/dts/arm/st/f3/stm32f3.dtsi:365 */
				status = "disabled";         /* in zephyr/dts/arm/st/f3/stm32f3.dtsi:366 */
				#pwm-cells = < 0x3 >;        /* in zephyr/dts/arm/st/f3/stm32f3.dtsi:367 */
			};

			/* node '/soc/timers@40014000/counter' defined in zephyr/dts/arm/st/f3/stm32f3.dtsi:370 */
			counter {
				compatible = "st,stm32-counter"; /* in zephyr/dts/arm/st/f3/stm32f3.dtsi:371 */
				status = "disabled";             /* in zephyr/dts/arm/st/f3/stm32f3.dtsi:372 */
			};
		};

		/* node '/soc/timers@40014400' defined in zephyr/dts/arm/st/f3/stm32f3.dtsi:376 */
		timers16: timers@40014400 {
			compatible = "st,stm32-timers"; /* in zephyr/dts/arm/st/f3/stm32f3.dtsi:377 */
			reg = < 0x40014400 0x400 >;     /* in zephyr/dts/arm/st/f3/stm32f3.dtsi:378 */
			resets = < &rctl 0x191 >;       /* in zephyr/dts/arm/st/f3/stm32f3.dtsi:381 */
			interrupts = < 0x19 0x0 >;      /* in zephyr/dts/arm/st/f3/stm32f3.dtsi:382 */
			interrupt-names = "global";     /* in zephyr/dts/arm/st/f3/stm32f3.dtsi:383 */
			st,prescaler = < 0x0 >;         /* in zephyr/dts/arm/st/f3/stm32f3.dtsi:384 */
			status = "disabled";            /* in zephyr/dts/arm/st/f3/stm32f3.dtsi:385 */
			clocks = < &rcc 0x18 0x20000 >,
			         < &rcc 0x7 0xb0030 >;  /* in zephyr/dts/arm/st/f3/stm32f303Xe.dtsi:102 */

			/* node '/soc/timers@40014400/pwm' defined in zephyr/dts/arm/st/f3/stm32f3.dtsi:387 */
			pwm {
				compatible = "st,stm32-pwm"; /* in zephyr/dts/arm/st/f3/stm32f3.dtsi:388 */
				status = "disabled";         /* in zephyr/dts/arm/st/f3/stm32f3.dtsi:389 */
				#pwm-cells = < 0x3 >;        /* in zephyr/dts/arm/st/f3/stm32f3.dtsi:390 */
			};

			/* node '/soc/timers@40014400/counter' defined in zephyr/dts/arm/st/f3/stm32f3.dtsi:393 */
			counter {
				compatible = "st,stm32-counter"; /* in zephyr/dts/arm/st/f3/stm32f3.dtsi:394 */
				status = "disabled";             /* in zephyr/dts/arm/st/f3/stm32f3.dtsi:395 */
			};
		};

		/* node '/soc/timers@40014800' defined in zephyr/dts/arm/st/f3/stm32f3.dtsi:399 */
		timers17: timers@40014800 {
			compatible = "st,stm32-timers"; /* in zephyr/dts/arm/st/f3/stm32f3.dtsi:400 */
			reg = < 0x40014800 0x400 >;     /* in zephyr/dts/arm/st/f3/stm32f3.dtsi:401 */
			resets = < &rctl 0x192 >;       /* in zephyr/dts/arm/st/f3/stm32f3.dtsi:404 */
			interrupts = < 0x1a 0x0 >;      /* in zephyr/dts/arm/st/f3/stm32f3.dtsi:405 */
			interrupt-names = "global";     /* in zephyr/dts/arm/st/f3/stm32f3.dtsi:406 */
			st,prescaler = < 0x0 >;         /* in zephyr/dts/arm/st/f3/stm32f3.dtsi:407 */
			status = "disabled";            /* in zephyr/dts/arm/st/f3/stm32f3.dtsi:408 */
			clocks = < &rcc 0x18 0x40000 >,
			         < &rcc 0x7 0xd0030 >;  /* in zephyr/dts/arm/st/f3/stm32f303Xe.dtsi:107 */

			/* node '/soc/timers@40014800/pwm' defined in zephyr/dts/arm/st/f3/stm32f3.dtsi:410 */
			pwm {
				compatible = "st,stm32-pwm"; /* in zephyr/dts/arm/st/f3/stm32f3.dtsi:411 */
				status = "disabled";         /* in zephyr/dts/arm/st/f3/stm32f3.dtsi:412 */
				#pwm-cells = < 0x3 >;        /* in zephyr/dts/arm/st/f3/stm32f3.dtsi:413 */
			};

			/* node '/soc/timers@40014800/counter' defined in zephyr/dts/arm/st/f3/stm32f3.dtsi:416 */
			counter {
				compatible = "st,stm32-counter"; /* in zephyr/dts/arm/st/f3/stm32f3.dtsi:417 */
				status = "disabled";             /* in zephyr/dts/arm/st/f3/stm32f3.dtsi:418 */
			};
		};

		/* node '/soc/rtc@40002800' defined in zephyr/dts/arm/st/f3/stm32f3.dtsi:422 */
		rtc: rtc@40002800 {
			compatible = "st,stm32-rtc";       /* in zephyr/dts/arm/st/f3/stm32f3.dtsi:423 */
			reg = < 0x40002800 0x400 >;        /* in zephyr/dts/arm/st/f3/stm32f3.dtsi:424 */
			interrupts = < 0x29 0x0 >;         /* in zephyr/dts/arm/st/f3/stm32f3.dtsi:426 */
			prescaler = < 0x8000 >;            /* in zephyr/dts/arm/st/f3/stm32f3.dtsi:427 */
			alarms-count = < 0x2 >;            /* in zephyr/dts/arm/st/f3/stm32f3.dtsi:428 */
			alrm-exti-line = < 0x11 >;         /* in zephyr/dts/arm/st/f3/stm32f3.dtsi:429 */
			clocks = < &rcc 0x1c 0x10000000 >,
			         < &rcc 0x3 0x2280020 >;   /* in zephyr/boards/st/nucleo_f303re/nucleo_f303re.dts:91 */
			status = "okay";                   /* in zephyr/boards/st/nucleo_f303re/nucleo_f303re.dts:93 */

			/* node '/soc/rtc@40002800/backup_regs' defined in zephyr/dts/arm/st/f3/stm32f303Xe.dtsi:150 */
			bbram: backup_regs {
				compatible = "st,stm32-bbram"; /* in zephyr/dts/arm/st/f3/stm32f303Xe.dtsi:151 */
				st,backup-regs = < 0x10 >;     /* in zephyr/dts/arm/st/f3/stm32f303Xe.dtsi:152 */
				status = "disabled";           /* in zephyr/dts/arm/st/f3/stm32f303Xe.dtsi:153 */
			};
		};

		/* node '/soc/can@40006400' defined in zephyr/dts/arm/st/f3/stm32f3.dtsi:433 */
		can1: can@40006400 {
			compatible = "st,stm32-bxcan";           /* in zephyr/dts/arm/st/f3/stm32f3.dtsi:434 */
			reg = < 0x40006400 0x400 >;              /* in zephyr/dts/arm/st/f3/stm32f3.dtsi:435 */
			interrupts = < 0x13 0x0 >,
			             < 0x14 0x0 >,
			             < 0x15 0x0 >,
			             < 0x16 0x0 >;               /* in zephyr/dts/arm/st/f3/stm32f3.dtsi:436 */
			interrupt-names = "TX",
			                  "RX0",
			                  "RX1",
			                  "SCE";                 /* in zephyr/dts/arm/st/f3/stm32f3.dtsi:437 */
			clocks = < &rcc 0x1c 0x2000000 >;        /* in zephyr/dts/arm/st/f3/stm32f3.dtsi:438 */
			pinctrl-0 = < &can_rx_pb8 &can_tx_pb9 >; /* in zephyr/boards/st/nucleo_f303re/nucleo_f303re.dts:97 */
			pinctrl-names = "default";               /* in zephyr/boards/st/nucleo_f303re/nucleo_f303re.dts:98 */
			status = "okay";                         /* in zephyr/boards/st/nucleo_f303re/nucleo_f303re.dts:99 */
		};

		/* node '/soc/dma@40020000' defined in zephyr/dts/arm/st/f3/stm32f3.dtsi:442 */
		dma1: dma@40020000 {
			compatible = "st,stm32-dma-v2bis";                                          /* in zephyr/dts/arm/st/f3/stm32f3.dtsi:443 */
			#dma-cells = < 0x2 >;                                                       /* in zephyr/dts/arm/st/f3/stm32f3.dtsi:444 */
			reg = < 0x40020000 0x400 >;                                                 /* in zephyr/dts/arm/st/f3/stm32f3.dtsi:445 */
			clocks = < &rcc 0x14 0x1 >;                                                 /* in zephyr/dts/arm/st/f3/stm32f3.dtsi:446 */
			interrupts = < 0xb 0x0 0xc 0x0 0xd 0x0 0xe 0x0 0xf 0x0 0x10 0x0 0x11 0x0 >; /* in zephyr/dts/arm/st/f3/stm32f3.dtsi:447 */
			status = "disabled";                                                        /* in zephyr/dts/arm/st/f3/stm32f3.dtsi:448 */
		};

		/* node '/soc/crc@40023000' defined in zephyr/dts/arm/st/f3/stm32f3.dtsi:451 */
		crc: crc@40023000 {
			compatible = "st,stm32-crc"; /* in zephyr/dts/arm/st/f3/stm32f3.dtsi:452 */
			reg = < 0x40023000 0x400 >;  /* in zephyr/dts/arm/st/f3/stm32f3.dtsi:453 */
			clocks = < &rcc 0x14 0x40 >; /* in zephyr/dts/arm/st/f3/stm32f3.dtsi:454 */
			resets = < &rctl 0x506 >;    /* in zephyr/dts/arm/st/f3/stm32f3.dtsi:455 */
			status = "disabled";         /* in zephyr/dts/arm/st/f3/stm32f3.dtsi:456 */
		};

		/* node '/soc/i2c@40005800' defined in zephyr/dts/arm/st/f3/stm32f303.dtsi:19 */
		i2c2: i2c@40005800 {
			compatible = "st,stm32-i2c-v2";  /* in zephyr/dts/arm/st/f3/stm32f303.dtsi:20 */
			clock-frequency = < 0x186a0 >;   /* in zephyr/dts/arm/st/f3/stm32f303.dtsi:21 */
			#address-cells = < 0x1 >;        /* in zephyr/dts/arm/st/f3/stm32f303.dtsi:22 */
			#size-cells = < 0x0 >;           /* in zephyr/dts/arm/st/f3/stm32f303.dtsi:23 */
			reg = < 0x40005800 0x400 >;      /* in zephyr/dts/arm/st/f3/stm32f303.dtsi:24 */
			clocks = < &rcc 0x1c 0x400000 >,
			         < &rcc 0x1 0x1050030 >; /* in zephyr/dts/arm/st/f3/stm32f303.dtsi:25 */
			interrupts = < 0x21 0x0 >,
			             < 0x22 0x0 >;       /* in zephyr/dts/arm/st/f3/stm32f303.dtsi:30 */
			interrupt-names = "event",
			                  "error";       /* in zephyr/dts/arm/st/f3/stm32f303.dtsi:31 */
			status = "disabled";             /* in zephyr/dts/arm/st/f3/stm32f303.dtsi:32 */
			phandle = < 0x18 >;              /* in zephyr/dts/arm/st/f3/stm32f303.dtsi:192 */
		};

		/* node '/soc/spi@40003800' defined in zephyr/dts/arm/st/f3/stm32f303.dtsi:35 */
		spi2: spi@40003800 {
			compatible = "st,stm32-spi-fifo",
			             "st,stm32-spi";            /* in zephyr/dts/arm/st/f3/stm32f303.dtsi:36 */
			#address-cells = < 0x1 >;               /* in zephyr/dts/arm/st/f3/stm32f303.dtsi:37 */
			#size-cells = < 0x0 >;                  /* in zephyr/dts/arm/st/f3/stm32f303.dtsi:38 */
			reg = < 0x40003800 0x400 >;             /* in zephyr/dts/arm/st/f3/stm32f303.dtsi:39 */
			clocks = < &rcc 0x1c 0x4000 >;          /* in zephyr/dts/arm/st/f3/stm32f303.dtsi:40 */
			interrupts = < 0x24 0x0 >;              /* in zephyr/dts/arm/st/f3/stm32f303.dtsi:41 */
			st,spi-data-width = "full-4-to-16-bit"; /* in zephyr/dts/arm/st/f3/stm32f303.dtsi:42 */
			status = "disabled";                    /* in zephyr/dts/arm/st/f3/stm32f303.dtsi:43 */
		};

		/* node '/soc/spi@40003c00' defined in zephyr/dts/arm/st/f3/stm32f303.dtsi:46 */
		spi3: spi@40003c00 {
			compatible = "st,stm32-spi-fifo",
			             "st,stm32-spi";            /* in zephyr/dts/arm/st/f3/stm32f303.dtsi:47 */
			#address-cells = < 0x1 >;               /* in zephyr/dts/arm/st/f3/stm32f303.dtsi:48 */
			#size-cells = < 0x0 >;                  /* in zephyr/dts/arm/st/f3/stm32f303.dtsi:49 */
			reg = < 0x40003c00 0x400 >;             /* in zephyr/dts/arm/st/f3/stm32f303.dtsi:50 */
			clocks = < &rcc 0x1c 0x8000 >;          /* in zephyr/dts/arm/st/f3/stm32f303.dtsi:51 */
			interrupts = < 0x33 0x0 >;              /* in zephyr/dts/arm/st/f3/stm32f303.dtsi:52 */
			st,spi-data-width = "full-4-to-16-bit"; /* in zephyr/dts/arm/st/f3/stm32f303.dtsi:53 */
			status = "disabled";                    /* in zephyr/dts/arm/st/f3/stm32f303.dtsi:54 */
		};

		/* node '/soc/serial@40005000' defined in zephyr/dts/arm/st/f3/stm32f303.dtsi:57 */
		uart5: serial@40005000 {
			compatible = "st,stm32-uart";    /* in zephyr/dts/arm/st/f3/stm32f303.dtsi:58 */
			reg = < 0x40005000 0x400 >;      /* in zephyr/dts/arm/st/f3/stm32f303.dtsi:59 */
			clocks = < &rcc 0x1c 0x100000 >; /* in zephyr/dts/arm/st/f3/stm32f303.dtsi:60 */
			resets = < &rctl 0x214 >;        /* in zephyr/dts/arm/st/f3/stm32f303.dtsi:61 */
			interrupts = < 0x35 0x0 >;       /* in zephyr/dts/arm/st/f3/stm32f303.dtsi:62 */
			status = "disabled";             /* in zephyr/dts/arm/st/f3/stm32f303.dtsi:63 */
		};

		/* node '/soc/timers@40012c00' defined in zephyr/dts/arm/st/f3/stm32f303.dtsi:76 */
		timers1: timers@40012c00 {
			compatible = "st,stm32-timers"; /* in zephyr/dts/arm/st/f3/stm32f303.dtsi:77 */
			reg = < 0x40012c00 0x400 >;     /* in zephyr/dts/arm/st/f3/stm32f303.dtsi:78 */
			clocks = < &rcc 0x18 0x800 >,
			         < &rcc 0x7 0x80030 >;  /* in zephyr/dts/arm/st/f3/stm32f303.dtsi:79 */
			resets = < &rctl 0x18b >;       /* in zephyr/dts/arm/st/f3/stm32f303.dtsi:81 */
			interrupts = < 0x18 0x0 >,
			             < 0x19 0x0 >,
			             < 0x1a 0x0 >,
			             < 0x1b 0x0 >;      /* in zephyr/dts/arm/st/f3/stm32f303.dtsi:82 */
			interrupt-names = "brk",
			                  "up",
			                  "trgcom",
			                  "cc";         /* in zephyr/dts/arm/st/f3/stm32f303.dtsi:83 */
			st,prescaler = < 0x0 >;         /* in zephyr/dts/arm/st/f3/stm32f303.dtsi:84 */
			status = "disabled";            /* in zephyr/dts/arm/st/f3/stm32f303.dtsi:85 */

			/* node '/soc/timers@40012c00/pwm' defined in zephyr/dts/arm/st/f3/stm32f303.dtsi:87 */
			pwm {
				compatible = "st,stm32-pwm"; /* in zephyr/dts/arm/st/f3/stm32f303.dtsi:88 */
				status = "disabled";         /* in zephyr/dts/arm/st/f3/stm32f303.dtsi:89 */
				#pwm-cells = < 0x3 >;        /* in zephyr/dts/arm/st/f3/stm32f303.dtsi:90 */
			};

			/* node '/soc/timers@40012c00/counter' defined in zephyr/dts/arm/st/f3/stm32f303.dtsi:93 */
			counter {
				compatible = "st,stm32-counter"; /* in zephyr/dts/arm/st/f3/stm32f303.dtsi:94 */
				status = "disabled";             /* in zephyr/dts/arm/st/f3/stm32f303.dtsi:95 */
			};

			/* node '/soc/timers@40012c00/qdec' defined in zephyr/dts/arm/st/f3/stm32f303.dtsi:98 */
			qdec {
				compatible = "st,stm32-qdec";    /* in zephyr/dts/arm/st/f3/stm32f303.dtsi:99 */
				st,input-filter-level = < 0x0 >; /* in zephyr/dts/arm/st/f3/stm32f303.dtsi:100 */
				status = "disabled";             /* in zephyr/dts/arm/st/f3/stm32f303.dtsi:101 */
			};
		};

		/* node '/soc/timers@40000400' defined in zephyr/dts/arm/st/f3/stm32f303.dtsi:105 */
		timers3: timers@40000400 {
			compatible = "st,stm32-timers"; /* in zephyr/dts/arm/st/f3/stm32f303.dtsi:106 */
			reg = < 0x40000400 0x400 >;     /* in zephyr/dts/arm/st/f3/stm32f303.dtsi:107 */
			resets = < &rctl 0x201 >;       /* in zephyr/dts/arm/st/f3/stm32f303.dtsi:110 */
			interrupts = < 0x1d 0x0 >;      /* in zephyr/dts/arm/st/f3/stm32f303.dtsi:111 */
			interrupt-names = "global";     /* in zephyr/dts/arm/st/f3/stm32f303.dtsi:112 */
			st,prescaler = < 0x0 >;         /* in zephyr/dts/arm/st/f3/stm32f303.dtsi:113 */
			status = "disabled";            /* in zephyr/dts/arm/st/f3/stm32f303.dtsi:114 */
			clocks = < &rcc 0x1c 0x2 >,
			         < &rcc 0x6 0x190030 >; /* in zephyr/dts/arm/st/f3/stm32f303Xe.dtsi:34 */

			/* node '/soc/timers@40000400/pwm' defined in zephyr/dts/arm/st/f3/stm32f303.dtsi:116 */
			pwm {
				compatible = "st,stm32-pwm"; /* in zephyr/dts/arm/st/f3/stm32f303.dtsi:117 */
				status = "disabled";         /* in zephyr/dts/arm/st/f3/stm32f303.dtsi:118 */
				#pwm-cells = < 0x3 >;        /* in zephyr/dts/arm/st/f3/stm32f303.dtsi:119 */
			};

			/* node '/soc/timers@40000400/counter' defined in zephyr/dts/arm/st/f3/stm32f303.dtsi:122 */
			counter {
				compatible = "st,stm32-counter"; /* in zephyr/dts/arm/st/f3/stm32f303.dtsi:123 */
				status = "disabled";             /* in zephyr/dts/arm/st/f3/stm32f303.dtsi:124 */
			};

			/* node '/soc/timers@40000400/qdec' defined in zephyr/dts/arm/st/f3/stm32f303.dtsi:127 */
			qdec {
				compatible = "st,stm32-qdec";    /* in zephyr/dts/arm/st/f3/stm32f303.dtsi:128 */
				st,input-filter-level = < 0x0 >; /* in zephyr/dts/arm/st/f3/stm32f303.dtsi:129 */
				status = "disabled";             /* in zephyr/dts/arm/st/f3/stm32f303.dtsi:130 */
			};
		};

		/* node '/soc/timers@40001400' defined in zephyr/dts/arm/st/f3/stm32f303.dtsi:134 */
		timers7: timers@40001400 {
			compatible = "st,stm32-timers"; /* in zephyr/dts/arm/st/f3/stm32f303.dtsi:135 */
			reg = < 0x40001400 0x400 >;     /* in zephyr/dts/arm/st/f3/stm32f303.dtsi:136 */
			clocks = < &rcc 0x1c 0x20 >,
			         < &rcc 0x6 0xff >;     /* in zephyr/dts/arm/st/f3/stm32f303.dtsi:137 */
			resets = < &rctl 0x205 >;       /* in zephyr/dts/arm/st/f3/stm32f303.dtsi:139 */
			interrupts = < 0x37 0x0 >;      /* in zephyr/dts/arm/st/f3/stm32f303.dtsi:140 */
			interrupt-names = "global";     /* in zephyr/dts/arm/st/f3/stm32f303.dtsi:141 */
			st,prescaler = < 0x0 >;         /* in zephyr/dts/arm/st/f3/stm32f303.dtsi:142 */
			status = "disabled";            /* in zephyr/dts/arm/st/f3/stm32f303.dtsi:143 */

			/* node '/soc/timers@40001400/counter' defined in zephyr/dts/arm/st/f3/stm32f303.dtsi:145 */
			counter {
				compatible = "st,stm32-counter"; /* in zephyr/dts/arm/st/f3/stm32f303.dtsi:146 */
				status = "disabled";             /* in zephyr/dts/arm/st/f3/stm32f303.dtsi:147 */
			};
		};

		/* node '/soc/adc@50000000' defined in zephyr/dts/arm/st/f3/stm32f303.dtsi:151 */
		adc1: adc@50000000 {
			compatible = "st,stm32-adc";                               /* in zephyr/dts/arm/st/f3/stm32f303.dtsi:152 */
			reg = < 0x50000000 0x400 >;                                /* in zephyr/dts/arm/st/f3/stm32f303.dtsi:153 */
			clocks = < &rcc 0x14 0x10000000 >;                         /* in zephyr/dts/arm/st/f3/stm32f303.dtsi:154 */
			clock-names = "adcx";                                      /* in zephyr/dts/arm/st/f3/stm32f303.dtsi:155 */
			interrupts = < 0x12 0x0 >;                                 /* in zephyr/dts/arm/st/f3/stm32f303.dtsi:156 */
			vref-mv = < 0xbb8 >;                                       /* in zephyr/dts/arm/st/f3/stm32f303.dtsi:157 */
			#io-channel-cells = < 0x1 >;                               /* in zephyr/dts/arm/st/f3/stm32f303.dtsi:158 */
			st,adc-resolutions = < 0xc 0xa 0x8 0x6 >;                  /* in zephyr/dts/arm/st/f3/stm32f303.dtsi:159 */
			sampling-times = < 0x2 0x3 0x5 0x8 0x14 0x3e 0xb6 0x25a >; /* in zephyr/dts/arm/st/f3/stm32f303.dtsi:160 */
			st,adc-sequencer = "programmable";                         /* in zephyr/dts/arm/st/f3/stm32f303.dtsi:161 */
			st,adc-oversampler = "none";                               /* in zephyr/dts/arm/st/f3/stm32f303.dtsi:162 */
			st,adc-internal-regulator = "startup-sw-delay";            /* in zephyr/dts/arm/st/f3/stm32f303.dtsi:163 */
			st,adc-has-differential-support;                           /* in zephyr/dts/arm/st/f3/stm32f303.dtsi:164 */
			st,adc-has-injected-support;                               /* in zephyr/dts/arm/st/f3/stm32f303.dtsi:165 */
			status = "disabled";                                       /* in zephyr/dts/arm/st/f3/stm32f303.dtsi:166 */
			phandle = < 0x15 >;                                        /* in zephyr/dts/arm/st/f3/stm32f3.dtsi:467 */
		};

		/* node '/soc/adc@50000100' defined in zephyr/dts/arm/st/f3/stm32f303.dtsi:169 */
		adc2: adc@50000100 {
			compatible = "st,stm32-adc";                               /* in zephyr/dts/arm/st/f3/stm32f303.dtsi:170 */
			reg = < 0x50000100 0x4c >;                                 /* in zephyr/dts/arm/st/f3/stm32f303.dtsi:171 */
			clocks = < &rcc 0x14 0x10000000 >;                         /* in zephyr/dts/arm/st/f3/stm32f303.dtsi:172 */
			clock-names = "adcx";                                      /* in zephyr/dts/arm/st/f3/stm32f303.dtsi:173 */
			interrupts = < 0x12 0x0 >;                                 /* in zephyr/dts/arm/st/f3/stm32f303.dtsi:174 */
			vref-mv = < 0xbb8 >;                                       /* in zephyr/dts/arm/st/f3/stm32f303.dtsi:175 */
			#io-channel-cells = < 0x1 >;                               /* in zephyr/dts/arm/st/f3/stm32f303.dtsi:176 */
			st,adc-resolutions = < 0xc 0xa 0x8 0x6 >;                  /* in zephyr/dts/arm/st/f3/stm32f303.dtsi:177 */
			sampling-times = < 0x2 0x3 0x5 0x8 0x14 0x3e 0xb6 0x25a >; /* in zephyr/dts/arm/st/f3/stm32f303.dtsi:178 */
			st,adc-sequencer = "programmable";                         /* in zephyr/dts/arm/st/f3/stm32f303.dtsi:179 */
			st,adc-oversampler = "none";                               /* in zephyr/dts/arm/st/f3/stm32f303.dtsi:180 */
			st,adc-internal-regulator = "startup-sw-delay";            /* in zephyr/dts/arm/st/f3/stm32f303.dtsi:181 */
			st,adc-has-differential-support;                           /* in zephyr/dts/arm/st/f3/stm32f303.dtsi:182 */
			st,adc-has-injected-support;                               /* in zephyr/dts/arm/st/f3/stm32f303.dtsi:183 */
			status = "disabled";                                       /* in zephyr/dts/arm/st/f3/stm32f303.dtsi:184 */
		};

		/* node '/soc/timers@40000800' defined in zephyr/dts/arm/st/f3/stm32f303Xe.dtsi:38 */
		timers4: timers@40000800 {
			compatible = "st,stm32-timers"; /* in zephyr/dts/arm/st/f3/stm32f303Xe.dtsi:39 */
			reg = < 0x40000800 0x400 >;     /* in zephyr/dts/arm/st/f3/stm32f303Xe.dtsi:40 */
			clocks = < &rcc 0x1c 0x4 >,
			         < &rcc 0x6 0x190030 >; /* in zephyr/dts/arm/st/f3/stm32f303Xe.dtsi:41 */
			resets = < &rctl 0x202 >;       /* in zephyr/dts/arm/st/f3/stm32f303Xe.dtsi:43 */
			interrupts = < 0x1e 0x0 >;      /* in zephyr/dts/arm/st/f3/stm32f303Xe.dtsi:44 */
			interrupt-names = "global";     /* in zephyr/dts/arm/st/f3/stm32f303Xe.dtsi:45 */
			st,prescaler = < 0x0 >;         /* in zephyr/dts/arm/st/f3/stm32f303Xe.dtsi:46 */
			status = "disabled";            /* in zephyr/dts/arm/st/f3/stm32f303Xe.dtsi:47 */

			/* node '/soc/timers@40000800/pwm' defined in zephyr/dts/arm/st/f3/stm32f303Xe.dtsi:49 */
			pwm {
				compatible = "st,stm32-pwm"; /* in zephyr/dts/arm/st/f3/stm32f303Xe.dtsi:50 */
				status = "disabled";         /* in zephyr/dts/arm/st/f3/stm32f303Xe.dtsi:51 */
				#pwm-cells = < 0x3 >;        /* in zephyr/dts/arm/st/f3/stm32f303Xe.dtsi:52 */
			};

			/* node '/soc/timers@40000800/counter' defined in zephyr/dts/arm/st/f3/stm32f303Xe.dtsi:55 */
			counter {
				compatible = "st,stm32-counter"; /* in zephyr/dts/arm/st/f3/stm32f303Xe.dtsi:56 */
				status = "disabled";             /* in zephyr/dts/arm/st/f3/stm32f303Xe.dtsi:57 */
			};

			/* node '/soc/timers@40000800/qdec' defined in zephyr/dts/arm/st/f3/stm32f303Xe.dtsi:60 */
			qdec {
				compatible = "st,stm32-qdec";    /* in zephyr/dts/arm/st/f3/stm32f303Xe.dtsi:61 */
				st,input-filter-level = < 0x0 >; /* in zephyr/dts/arm/st/f3/stm32f303Xe.dtsi:62 */
				status = "disabled";             /* in zephyr/dts/arm/st/f3/stm32f303Xe.dtsi:63 */
			};
		};

		/* node '/soc/timers@40013400' defined in zephyr/dts/arm/st/f3/stm32f303Xe.dtsi:67 */
		timers8: timers@40013400 {
			compatible = "st,stm32-timers"; /* in zephyr/dts/arm/st/f3/stm32f303Xe.dtsi:68 */
			reg = < 0x40013400 0x400 >;     /* in zephyr/dts/arm/st/f3/stm32f303Xe.dtsi:69 */
			clocks = < &rcc 0x18 0x2000 >,
			         < &rcc 0x7 0x90030 >;  /* in zephyr/dts/arm/st/f3/stm32f303Xe.dtsi:70 */
			resets = < &rctl 0x18d >;       /* in zephyr/dts/arm/st/f3/stm32f303Xe.dtsi:72 */
			interrupts = < 0x2b 0x0 >,
			             < 0x2c 0x0 >,
			             < 0x2d 0x0 >,
			             < 0x2e 0x0 >;      /* in zephyr/dts/arm/st/f3/stm32f303Xe.dtsi:73 */
			interrupt-names = "brk",
			                  "up",
			                  "trgcom",
			                  "cc";         /* in zephyr/dts/arm/st/f3/stm32f303Xe.dtsi:74 */
			st,prescaler = < 0x0 >;         /* in zephyr/dts/arm/st/f3/stm32f303Xe.dtsi:75 */
			status = "disabled";            /* in zephyr/dts/arm/st/f3/stm32f303Xe.dtsi:76 */

			/* node '/soc/timers@40013400/pwm' defined in zephyr/dts/arm/st/f3/stm32f303Xe.dtsi:78 */
			pwm {
				compatible = "st,stm32-pwm"; /* in zephyr/dts/arm/st/f3/stm32f303Xe.dtsi:79 */
				status = "disabled";         /* in zephyr/dts/arm/st/f3/stm32f303Xe.dtsi:80 */
				#pwm-cells = < 0x3 >;        /* in zephyr/dts/arm/st/f3/stm32f303Xe.dtsi:81 */
			};

			/* node '/soc/timers@40013400/counter' defined in zephyr/dts/arm/st/f3/stm32f303Xe.dtsi:84 */
			counter {
				compatible = "st,stm32-counter"; /* in zephyr/dts/arm/st/f3/stm32f303Xe.dtsi:85 */
				status = "disabled";             /* in zephyr/dts/arm/st/f3/stm32f303Xe.dtsi:86 */
			};

			/* node '/soc/timers@40013400/qdec' defined in zephyr/dts/arm/st/f3/stm32f303Xe.dtsi:89 */
			qdec {
				compatible = "st,stm32-qdec";    /* in zephyr/dts/arm/st/f3/stm32f303Xe.dtsi:90 */
				st,input-filter-level = < 0x0 >; /* in zephyr/dts/arm/st/f3/stm32f303Xe.dtsi:91 */
				status = "disabled";             /* in zephyr/dts/arm/st/f3/stm32f303Xe.dtsi:92 */
			};
		};

		/* node '/soc/timers@40015000' defined in zephyr/dts/arm/st/f3/stm32f303Xe.dtsi:111 */
		timers20: timers@40015000 {
			compatible = "st,stm32-timers";  /* in zephyr/dts/arm/st/f3/stm32f303Xe.dtsi:112 */
			reg = < 0x40015000 0x400 >;      /* in zephyr/dts/arm/st/f3/stm32f303Xe.dtsi:113 */
			clocks = < &rcc 0x18 0x100000 >,
			         < &rcc 0x7 0xf0030 >;   /* in zephyr/dts/arm/st/f3/stm32f303Xe.dtsi:114 */
			resets = < &rctl 0x194 >;        /* in zephyr/dts/arm/st/f3/stm32f303Xe.dtsi:116 */
			interrupts = < 0x4d 0x0 >,
			             < 0x4e 0x0 >,
			             < 0x4f 0x0 >,
			             < 0x50 0x0 >;       /* in zephyr/dts/arm/st/f3/stm32f303Xe.dtsi:117 */
			interrupt-names = "brk",
			                  "up",
			                  "trgcom",
			                  "cc";          /* in zephyr/dts/arm/st/f3/stm32f303Xe.dtsi:118 */
			st,prescaler = < 0x0 >;          /* in zephyr/dts/arm/st/f3/stm32f303Xe.dtsi:119 */
			status = "disabled";             /* in zephyr/dts/arm/st/f3/stm32f303Xe.dtsi:120 */

			/* node '/soc/timers@40015000/pwm' defined in zephyr/dts/arm/st/f3/stm32f303Xe.dtsi:122 */
			pwm {
				compatible = "st,stm32-pwm"; /* in zephyr/dts/arm/st/f3/stm32f303Xe.dtsi:123 */
				status = "disabled";         /* in zephyr/dts/arm/st/f3/stm32f303Xe.dtsi:124 */
				#pwm-cells = < 0x3 >;        /* in zephyr/dts/arm/st/f3/stm32f303Xe.dtsi:125 */
			};

			/* node '/soc/timers@40015000/counter' defined in zephyr/dts/arm/st/f3/stm32f303Xe.dtsi:128 */
			counter {
				compatible = "st,stm32-counter"; /* in zephyr/dts/arm/st/f3/stm32f303Xe.dtsi:129 */
				status = "disabled";             /* in zephyr/dts/arm/st/f3/stm32f303Xe.dtsi:130 */
			};

			/* node '/soc/timers@40015000/qdec' defined in zephyr/dts/arm/st/f3/stm32f303Xe.dtsi:133 */
			qdec {
				compatible = "st,stm32-qdec";    /* in zephyr/dts/arm/st/f3/stm32f303Xe.dtsi:134 */
				st,input-filter-level = < 0x0 >; /* in zephyr/dts/arm/st/f3/stm32f303Xe.dtsi:135 */
				status = "disabled";             /* in zephyr/dts/arm/st/f3/stm32f303Xe.dtsi:136 */
			};
		};

		/* node '/soc/dma@40020400' defined in zephyr/dts/arm/st/f3/stm32f303Xe.dtsi:140 */
		dma2: dma@40020400 {
			compatible = "st,stm32-dma-v2bis";                             /* in zephyr/dts/arm/st/f3/stm32f303Xe.dtsi:141 */
			#dma-cells = < 0x2 >;                                          /* in zephyr/dts/arm/st/f3/stm32f303Xe.dtsi:142 */
			reg = < 0x40020400 0x400 >;                                    /* in zephyr/dts/arm/st/f3/stm32f303Xe.dtsi:143 */
			clocks = < &rcc 0x14 0x2 >;                                    /* in zephyr/dts/arm/st/f3/stm32f303Xe.dtsi:144 */
			interrupts = < 0x38 0x0 0x39 0x0 0x3a 0x0 0x3b 0x0 0x3c 0x0 >; /* in zephyr/dts/arm/st/f3/stm32f303Xe.dtsi:145 */
			status = "disabled";                                           /* in zephyr/dts/arm/st/f3/stm32f303Xe.dtsi:146 */
		};

		/* node '/soc/i2c@40007800' defined in zephyr/dts/arm/st/f3/stm32f303Xe.dtsi:157 */
		i2c3: i2c@40007800 {
			compatible = "st,stm32-i2c-v2";    /* in zephyr/dts/arm/st/f3/stm32f303Xe.dtsi:158 */
			clock-frequency = < 0x186a0 >;     /* in zephyr/dts/arm/st/f3/stm32f303Xe.dtsi:159 */
			#address-cells = < 0x1 >;          /* in zephyr/dts/arm/st/f3/stm32f303Xe.dtsi:160 */
			#size-cells = < 0x0 >;             /* in zephyr/dts/arm/st/f3/stm32f303Xe.dtsi:161 */
			reg = < 0x40007800 0x400 >;        /* in zephyr/dts/arm/st/f3/stm32f303Xe.dtsi:162 */
			clocks = < &rcc 0x1c 0x40000000 >,
			         < &rcc 0x1 0x1060030 >;   /* in zephyr/dts/arm/st/f3/stm32f303Xe.dtsi:163 */
			interrupts = < 0x48 0x0 >,
			             < 0x49 0x0 >;         /* in zephyr/dts/arm/st/f3/stm32f303Xe.dtsi:168 */
			interrupt-names = "event",
			                  "error";         /* in zephyr/dts/arm/st/f3/stm32f303Xe.dtsi:169 */
			status = "disabled";               /* in zephyr/dts/arm/st/f3/stm32f303Xe.dtsi:170 */
		};
	};

	/* node '/cpus' defined in zephyr/dts/arm/st/f3/stm32f3.dtsi:28 */
	cpus {
		#address-cells = < 0x1 >; /* in zephyr/dts/arm/st/f3/stm32f3.dtsi:29 */
		#size-cells = < 0x0 >;    /* in zephyr/dts/arm/st/f3/stm32f3.dtsi:30 */

		/* node '/cpus/cpu@0' defined in zephyr/dts/arm/st/f3/stm32f3.dtsi:32 */
		cpu0: cpu@0 {
			device_type = "cpu";           /* in zephyr/dts/arm/st/f3/stm32f3.dtsi:33 */
			compatible = "arm,cortex-m4f"; /* in zephyr/dts/arm/st/f3/stm32f3.dtsi:34 */
			reg = < 0x0 >;                 /* in zephyr/dts/arm/st/f3/stm32f3.dtsi:35 */
		};
	};

	/* node '/memory@20000000' defined in zephyr/dts/arm/st/f3/stm32f3.dtsi:39 */
	sram0: memory@20000000 {
		compatible = "zephyr,memory-region",
		             "mmio-sram";            /* in zephyr/dts/arm/st/f3/stm32f3.dtsi:40 */
		zephyr,memory-region = "SRAM0";      /* in zephyr/dts/arm/st/f3/stm32f3.dtsi:41 */
		reg = < 0x20000000 0x10000 >;        /* in zephyr/dts/arm/st/f3/stm32f303Xe.dtsi:17 */
	};

	/* node '/clocks' defined in zephyr/dts/arm/st/f3/stm32f3.dtsi:44 */
	clocks {

		/* node '/clocks/clk-hse' defined in zephyr/dts/arm/st/f3/stm32f3.dtsi:45 */
		clk_hse: clk-hse {
			#clock-cells = < 0x0 >;            /* in zephyr/dts/arm/st/f3/stm32f3.dtsi:46 */
			compatible = "st,stm32-hse-clock"; /* in zephyr/dts/arm/st/f3/stm32f3.dtsi:47 */
			hse-bypass;                        /* in zephyr/boards/st/nucleo_f303re/nucleo_f303re.dts:56 */
			clock-frequency = < 0x7a1200 >;    /* in zephyr/boards/st/nucleo_f303re/nucleo_f303re.dts:57 */
			status = "okay";                   /* in zephyr/boards/st/nucleo_f303re/nucleo_f303re.dts:58 */
			phandle = < 0x12 >;                /* in zephyr/boards/st/nucleo_f303re/nucleo_f303re.dts:64 */
		};

		/* node '/clocks/clk-hsi' defined in zephyr/dts/arm/st/f3/stm32f3.dtsi:51 */
		clk_hsi: clk-hsi {
			#clock-cells = < 0x0 >;         /* in zephyr/dts/arm/st/f3/stm32f3.dtsi:52 */
			compatible = "fixed-clock";     /* in zephyr/dts/arm/st/f3/stm32f3.dtsi:53 */
			clock-frequency = < 0x7a1200 >; /* in zephyr/dts/arm/st/f3/stm32f3.dtsi:54 */
			status = "disabled";            /* in zephyr/dts/arm/st/f3/stm32f3.dtsi:55 */
		};

		/* node '/clocks/clk-lse' defined in zephyr/dts/arm/st/f3/stm32f3.dtsi:58 */
		clk_lse: clk-lse {
			#clock-cells = < 0x0 >;            /* in zephyr/dts/arm/st/f3/stm32f3.dtsi:59 */
			compatible = "st,stm32-lse-clock"; /* in zephyr/dts/arm/st/f3/stm32f3.dtsi:60 */
			clock-frequency = < 0x8000 >;      /* in zephyr/dts/arm/st/f3/stm32f3.dtsi:61 */
			driving-capability = < 0x0 >;      /* in zephyr/dts/arm/st/f3/stm32f3.dtsi:62 */
			status = "disabled";               /* in zephyr/dts/arm/st/f3/stm32f3.dtsi:63 */
		};

		/* node '/clocks/clk-lsi' defined in zephyr/dts/arm/st/f3/stm32f3.dtsi:66 */
		clk_lsi: clk-lsi {
			#clock-cells = < 0x0 >;       /* in zephyr/dts/arm/st/f3/stm32f3.dtsi:67 */
			compatible = "fixed-clock";   /* in zephyr/dts/arm/st/f3/stm32f3.dtsi:68 */
			clock-frequency = < 0x9c40 >; /* in zephyr/dts/arm/st/f3/stm32f3.dtsi:69 */
			status = "okay";              /* in zephyr/boards/st/nucleo_f303re/nucleo_f303re.dts:52 */
		};

		/* node '/clocks/pll' defined in zephyr/dts/arm/st/f3/stm32f3.dtsi:73 */
		pll: pll {
			#clock-cells = < 0x0 >;              /* in zephyr/dts/arm/st/f3/stm32f3.dtsi:74 */
			compatible = "st,stm32f0-pll-clock"; /* in zephyr/dts/arm/st/f3/stm32f3.dtsi:75 */
			prediv = < 0x1 >;                    /* in zephyr/boards/st/nucleo_f303re/nucleo_f303re.dts:62 */
			mul = < 0x9 >;                       /* in zephyr/boards/st/nucleo_f303re/nucleo_f303re.dts:63 */
			clocks = < &clk_hse >;               /* in zephyr/boards/st/nucleo_f303re/nucleo_f303re.dts:64 */
			status = "okay";                     /* in zephyr/boards/st/nucleo_f303re/nucleo_f303re.dts:65 */
			phandle = < 0x3 >;                   /* in zephyr/boards/st/nucleo_f303re/nucleo_f303re.dts:69 */
		};
	};

	/* node '/dietemp' defined in zephyr/dts/arm/st/f3/stm32f3.dtsi:460 */
	die_temp: dietemp {
		compatible = "st,stm32-temp-cal"; /* in zephyr/dts/arm/st/f3/stm32f3.dtsi:461 */
		nvmem-cells = < &ts_cal1_otp >,
		              < &ts_cal2_otp >;   /* in zephyr/dts/arm/st/f3/stm32f3.dtsi:462 */
		nvmem-cell-names = "TS_CAL1",
		                   "TS_CAL2";     /* in zephyr/dts/arm/st/f3/stm32f3.dtsi:463 */
		ts-cal1-temp = < 0x1e >;          /* in zephyr/dts/arm/st/f3/stm32f3.dtsi:464 */
		ts-cal2-temp = < 0x6e >;          /* in zephyr/dts/arm/st/f3/stm32f3.dtsi:465 */
		ts-cal-vrefanalog = < 0xce4 >;    /* in zephyr/dts/arm/st/f3/stm32f3.dtsi:466 */
		io-channels = < &adc1 0x10 >;     /* in zephyr/dts/arm/st/f3/stm32f3.dtsi:467 */
		status = "disabled";              /* in zephyr/dts/arm/st/f3/stm32f3.dtsi:468 */
	};

	/* node '/vref' defined in zephyr/dts/arm/st/f3/stm32f3.dtsi:471 */
	vref: vref {
		compatible = "st,stm32-vref";   /* in zephyr/dts/arm/st/f3/stm32f3.dtsi:472 */
		nvmem-cells = < &vrefint_otp >; /* in zephyr/dts/arm/st/f3/stm32f3.dtsi:473 */
		vrefint-cal-mv = < 0xce4 >;     /* in zephyr/dts/arm/st/f3/stm32f3.dtsi:474 */
		io-channels = < &adc1 0x12 >;   /* in zephyr/dts/arm/st/f3/stm32f3.dtsi:475 */
		status = "disabled";            /* in zephyr/dts/arm/st/f3/stm32f3.dtsi:476 */
	};

	/* node '/vbat' defined in zephyr/dts/arm/st/f3/stm32f3.dtsi:479 */
	vbat: vbat {
		compatible = "st,stm32-vbat"; /* in zephyr/dts/arm/st/f3/stm32f3.dtsi:480 */
		ratio = < 0x2 >;              /* in zephyr/dts/arm/st/f3/stm32f3.dtsi:481 */
		io-channels = < &adc1 0x11 >; /* in zephyr/dts/arm/st/f3/stm32f3.dtsi:482 */
		status = "disabled";          /* in zephyr/dts/arm/st/f3/stm32f3.dtsi:483 */
	};

	/* node '/usbphy' defined in zephyr/dts/arm/st/f3/stm32f3.dtsi:486 */
	usb_fs_phy: usbphy {
		compatible = "usb-nop-xceiv"; /* in zephyr/dts/arm/st/f3/stm32f3.dtsi:487 */
		#phy-cells = < 0x0 >;         /* in zephyr/dts/arm/st/f3/stm32f3.dtsi:488 */
		phandle = < 0xf >;            /* in zephyr/dts/arm/st/f3/stm32f3.dtsi:302 */
	};

	/* node '/smbus1' defined in zephyr/dts/arm/st/f3/stm32f3.dtsi:491 */
	smbus1: smbus1 {
		compatible = "st,stm32-smbus"; /* in zephyr/dts/arm/st/f3/stm32f3.dtsi:492 */
		#address-cells = < 0x1 >;      /* in zephyr/dts/arm/st/f3/stm32f3.dtsi:493 */
		#size-cells = < 0x0 >;         /* in zephyr/dts/arm/st/f3/stm32f3.dtsi:494 */
		i2c = < &i2c1 >;               /* in zephyr/dts/arm/st/f3/stm32f3.dtsi:495 */
		status = "disabled";           /* in zephyr/dts/arm/st/f3/stm32f3.dtsi:496 */
	};

	/* node '/smbus2' defined in zephyr/dts/arm/st/f3/stm32f303.dtsi:188 */
	smbus2: smbus2 {
		compatible = "st,stm32-smbus"; /* in zephyr/dts/arm/st/f3/stm32f303.dtsi:189 */
		#address-cells = < 0x1 >;      /* in zephyr/dts/arm/st/f3/stm32f303.dtsi:190 */
		#size-cells = < 0x0 >;         /* in zephyr/dts/arm/st/f3/stm32f303.dtsi:191 */
		i2c = < &i2c2 >;               /* in zephyr/dts/arm/st/f3/stm32f303.dtsi:192 */
		status = "disabled";           /* in zephyr/dts/arm/st/f3/stm32f303.dtsi:193 */
	};

	/* node '/memory@10000000' defined in zephyr/dts/arm/st/f3/stm32f303Xe.dtsi:10 */
	ccm0: memory@10000000 {
		compatible = "zephyr,memory-region",
		             "st,stm32-ccm";         /* in zephyr/dts/arm/st/f3/stm32f303Xe.dtsi:11 */
		reg = < 0x10000000 0x4000 >;         /* in zephyr/dts/arm/st/f3/stm32f303Xe.dtsi:12 */
		zephyr,memory-region = "DTCM";       /* in zephyr/dts/arm/st/f3/stm32f303Xe.dtsi:13 */
	};

	/* node '/connector' defined in zephyr/boards/st/nucleo_f303re/arduino_r3_connector.dtsi:10 */
	arduino_header: connector {
		compatible = "arduino-header-r3";          /* in zephyr/boards/st/nucleo_f303re/arduino_r3_connector.dtsi:11 */
		#gpio-cells = < 0x2 >;                     /* in zephyr/boards/st/nucleo_f303re/arduino_r3_connector.dtsi:12 */
		gpio-map-mask = < 0xffffffff 0xffffffc0 >; /* in zephyr/boards/st/nucleo_f303re/arduino_r3_connector.dtsi:13 */
		gpio-map-pass-thru = < 0x0 0x3f >;         /* in zephyr/boards/st/nucleo_f303re/arduino_r3_connector.dtsi:14 */
		gpio-map = < 0x0 0x0 &gpioa 0x0 0x0 >,
		           < 0x1 0x0 &gpioa 0x1 0x0 >,
		           < 0x2 0x0 &gpioa 0x4 0x0 >,
		           < 0x3 0x0 &gpiob 0x0 0x0 >,
		           < 0x4 0x0 &gpioc 0x1 0x0 >,
		           < 0x5 0x0 &gpioc 0x0 0x0 >,
		           < 0x6 0x0 &gpioa 0x3 0x0 >,
		           < 0x7 0x0 &gpioa 0x2 0x0 >,
		           < 0x8 0x0 &gpioa 0xa 0x0 >,
		           < 0x9 0x0 &gpiob 0x3 0x0 >,
		           < 0xa 0x0 &gpiob 0x5 0x0 >,
		           < 0xb 0x0 &gpiob 0x4 0x0 >,
		           < 0xc 0x0 &gpiob 0xa 0x0 >,
		           < 0xd 0x0 &gpioa 0x8 0x0 >,
		           < 0xe 0x0 &gpioa 0x9 0x0 >,
		           < 0xf 0x0 &gpioc 0x7 0x0 >,
		           < 0x10 0x0 &gpiob 0x6 0x0 >,
		           < 0x11 0x0 &gpiob 0xf 0x0 >,
		           < 0x12 0x0 &gpiob 0xe 0x0 >,
		           < 0x13 0x0 &gpiob 0xd 0x0 >,
		           < 0x14 0x0 &gpiob 0x9 0x0 >,
		           < 0x15 0x0 &gpiob 0x8 0x0 >;    /* in zephyr/boards/st/nucleo_f303re/arduino_r3_connector.dtsi:15 */
	};

	/* node '/st-morpho-header' defined in zephyr/boards/st/nucleo_f303re/st_morpho_connector.dtsi:10 */
	st_morpho_header: st-morpho-header {
		compatible = "st-morpho-header";        /* in zephyr/boards/st/nucleo_f303re/st_morpho_connector.dtsi:11 */
		#gpio-cells = < 0x2 >;                  /* in zephyr/boards/st/nucleo_f303re/st_morpho_connector.dtsi:12 */
		gpio-map-mask = < 0xff 0x0 >;           /* in zephyr/boards/st/nucleo_f303re/st_morpho_connector.dtsi:13 */
		gpio-map-pass-thru = < 0x0 0x7f >;      /* in zephyr/boards/st/nucleo_f303re/st_morpho_connector.dtsi:14 */
		gpio-map = < 0x0 0x0 &gpioc 0xa 0x0 >,
		           < 0x1 0x0 &gpioc 0xb 0x0 >,
		           < 0x2 0x0 &gpioc 0xc 0x0 >,
		           < 0x3 0x0 &gpiod 0x2 0x0 >,
		           < 0xc 0x0 &gpioa 0xd 0x0 >,
		           < 0xe 0x0 &gpioa 0xe 0x0 >,
		           < 0x10 0x0 &gpioa 0xf 0x0 >,
		           < 0x14 0x0 &gpiob 0x7 0x0 >,
		           < 0x16 0x0 &gpioc 0xd 0x0 >,
		           < 0x18 0x0 &gpioc 0xe 0x0 >,
		           < 0x1a 0x0 &gpioc 0xf 0x0 >,
		           < 0x1b 0x0 &gpioa 0x0 0x0 >,
		           < 0x1c 0x0 &gpiof 0x0 0x0 >,
		           < 0x1d 0x0 &gpioa 0x1 0x0 >,
		           < 0x1e 0x0 &gpiof 0x1 0x0 >,
		           < 0x1f 0x0 &gpioa 0x4 0x0 >,
		           < 0x21 0x0 &gpiob 0x0 0x0 >,
		           < 0x22 0x0 &gpioc 0x2 0x0 >,
		           < 0x23 0x0 &gpioc 0x1 0x0 >,
		           < 0x24 0x0 &gpioc 0x3 0x0 >,
		           < 0x25 0x0 &gpioc 0x0 0x0 >,
		           < 0x48 0x0 &gpioc 0x9 0x0 >,
		           < 0x49 0x0 &gpioc 0x8 0x0 >,
		           < 0x4a 0x0 &gpiob 0x8 0x0 >,
		           < 0x4b 0x0 &gpioc 0x6 0x0 >,
		           < 0x4c 0x0 &gpiob 0x9 0x0 >,
		           < 0x4d 0x0 &gpioc 0x5 0x0 >,
		           < 0x52 0x0 &gpioa 0x5 0x0 >,
		           < 0x53 0x0 &gpioa 0xc 0x0 >,
		           < 0x54 0x0 &gpioa 0x6 0x0 >,
		           < 0x55 0x0 &gpioa 0xb 0x0 >,
		           < 0x56 0x0 &gpioa 0x7 0x0 >,
		           < 0x57 0x0 &gpiob 0xc 0x0 >,
		           < 0x58 0x0 &gpiob 0x6 0x0 >,
		           < 0x59 0x0 &gpiob 0xb 0x0 >,
		           < 0x5a 0x0 &gpioc 0x7 0x0 >,
		           < 0x5c 0x0 &gpioa 0x9 0x0 >,
		           < 0x5d 0x0 &gpiob 0x2 0x0 >,
		           < 0x5e 0x0 &gpioa 0x8 0x0 >,
		           < 0x5f 0x0 &gpiob 0x1 0x0 >,
		           < 0x60 0x0 &gpiob 0xa 0x0 >,
		           < 0x61 0x0 &gpiob 0xf 0x0 >,
		           < 0x62 0x0 &gpiob 0x4 0x0 >,
		           < 0x63 0x0 &gpiob 0xe 0x0 >,
		           < 0x64 0x0 &gpiob 0x5 0x0 >,
		           < 0x65 0x0 &gpiob 0xd 0x0 >,
		           < 0x66 0x0 &gpiob 0x3 0x0 >,
		           < 0x68 0x0 &gpioa 0xa 0x0 >,
		           < 0x69 0x0 &gpioc 0x4 0x0 >,
		           < 0x6a 0x0 &gpioa 0x2 0x0 >,
		           < 0x6c 0x0 &gpioa 0x3 0x0 >; /* in zephyr/boards/st/nucleo_f303re/st_morpho_connector.dtsi:15 */
	};

	/* node '/leds' defined in zephyr/boards/st/nucleo_f303re/nucleo_f303re.dts:26 */
	leds: leds {
		compatible = "gpio-leds"; /* in zephyr/boards/st/nucleo_f303re/nucleo_f303re.dts:27 */

		/* node '/leds/led_2' defined in zephyr/boards/st/nucleo_f303re/nucleo_f303re.dts:29 */
		green_led_2: led_2 {
			gpios = < &gpioa 0x5 0x0 >; /* in zephyr/boards/st/nucleo_f303re/nucleo_f303re.dts:30 */
			label = "User LD2";         /* in zephyr/boards/st/nucleo_f303re/nucleo_f303re.dts:31 */
		};
	};

	/* node '/gpio_keys' defined in zephyr/boards/st/nucleo_f303re/nucleo_f303re.dts:35 */
	gpio_keys {
		compatible = "gpio-keys"; /* in zephyr/boards/st/nucleo_f303re/nucleo_f303re.dts:36 */

		/* node '/gpio_keys/button' defined in zephyr/boards/st/nucleo_f303re/nucleo_f303re.dts:38 */
		user_button: button {
			label = "User";             /* in zephyr/boards/st/nucleo_f303re/nucleo_f303re.dts:39 */
			gpios = < &gpioc 0xd 0x1 >; /* in zephyr/boards/st/nucleo_f303re/nucleo_f303re.dts:40 */
			zephyr,code = < 0xb >;      /* in zephyr/boards/st/nucleo_f303re/nucleo_f303re.dts:41 */
		};
	};
};
